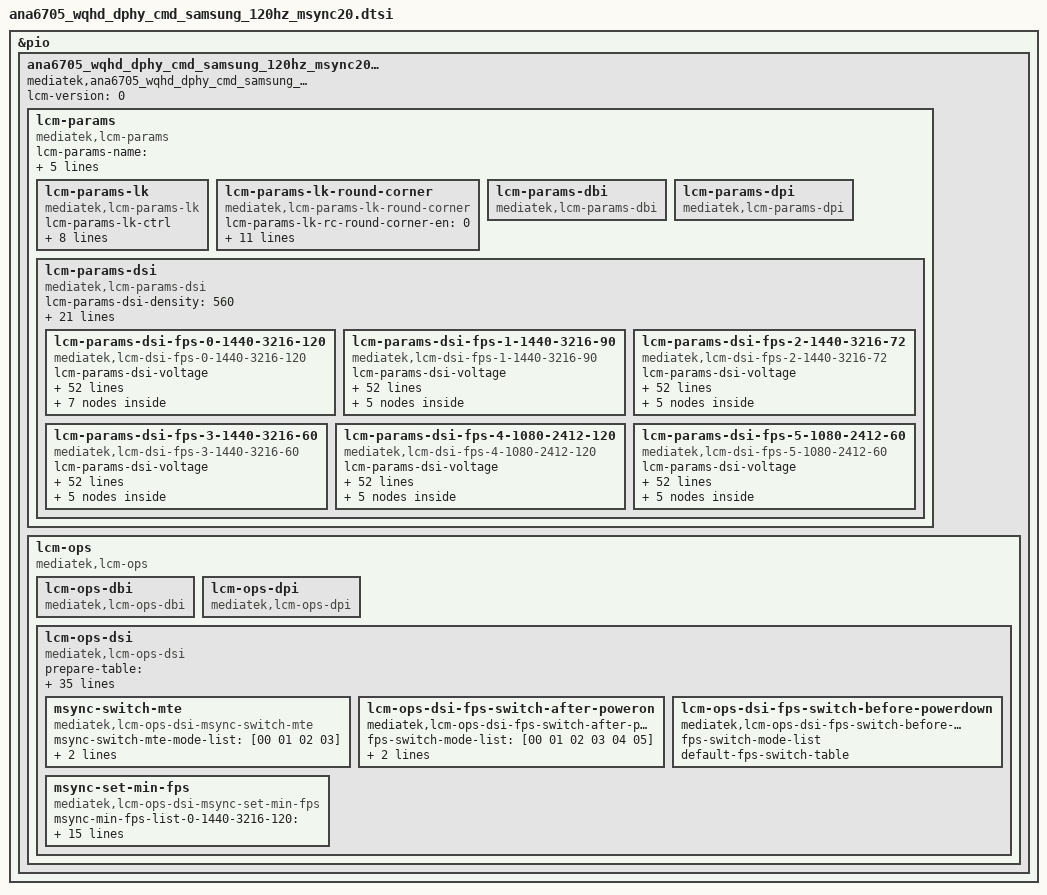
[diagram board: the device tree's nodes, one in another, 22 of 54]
// SPDX-License-Identifier: GPL-2.0-only OR BSD-2-Clause
/*
 * Device Tree defines for LCM settings
 * Copyright (c) 2021 MediaTek Inc.
 */

#include "mtk_lcm_settings.h"

&pio {
	ana6705_wqhd_dphy_cmd_samsung_120hz_msync20: ana6705-wqhd-dphy-cmd-samsung-120hz-msync20 {
		compatible = "mediatek,ana6705_wqhd_dphy_cmd_samsung_120hz_msync20";
		lcm-version = <0>;

		lcm-params{
			compatible = "mediatek,lcm-params";
			lcm-params-name = "ana6705-wqhd-dphy-cmd-samsung-120hz-msync20";
			lcm-params-types = <MTK_LCM_FUNC_DSI>;
			lcm-params-resolution = <1440 3216>;
			lcm-params-physical-width = <67>;
			lcm-params-physical-height = <149>;

			/* lk support */
			lcm-params-lk {
				compatible = "mediatek,lcm-params-lk";
				lcm-params-lk-ctrl;
				lcm-params-lk-lcm-if;
				lcm-params-lk-lcm-cmd-if;
				lcm-params-lk-io-select-mode;
				lcm-params-lk-lcm-x;
				lcm-params-lk-lcm-y;
				lcm-params-lk-virtual-resolution = <0 0>;
				lcm-params-lk-od-table-size;
				lcm-params-lk-od-table;
			};

			lcm-params-lk-round-corner {
				compatible = "mediatek,lcm-params-lk-round-corner";
				lcm-params-lk-rc-round-corner-en = <0>;
				lcm-params-lk-rc-is-notch;
				lcm-params-lk-rc-full-content = <0>;
				lcm-params-lk-rc-width;
				lcm-params-lk-rc-height;
				lcm-params-lk-rc-width-bot;
				lcm-params-lk-rc-height-bot;
				lcm-params-lk-rc-top-size;
				lcm-params-lk-rc-top-size-left;
				lcm-params-lk-rc-top-size-right;
				lcm-params-lk-rc-bottom-size;
				lcm-params-lk-rc-pattern-name;
			};

			lcm-params-dbi {
				compatible = "mediatek,lcm-params-dbi";
				/* future reserved for dbi interfaces */
			};

			lcm-params-dpi {
				compatible = "mediatek,lcm-params-dpi";
				/* future reserved for dpi interfaces */
			};

			lcm-params-dsi {
				compatible = "mediatek,lcm-params-dsi";
				lcm-params-dsi-density = <560>;
				lcm-params-dsi-lanes = <4>;
				lcm-params-dsi-format = <MTK_MIPI_DSI_FMT_RGB888>;
				lcm-params-dsi-phy-type = <MTK_LCM_MIPI_DPHY>;
				lcm-params-dsi-mode-flags = <MTK_MIPI_DSI_MODE_LPM>,
						<MTK_MIPI_DSI_MODE_EOT_PACKET>,
						<MTK_MIPI_DSI_CLOCK_NON_CONTINUOUS>;
				lcm-params-dsi-mode-flags-doze-on;
				lcm-params-dsi-mode-flags-doze-off;

				lcm-params-dsi-need-fake-resolution;
				lcm-params-dsi-fake-resolution;

				lcm-gpio-list = <&pio 42 0>, /* gpio list*/
					<&pio 28 0>,
					<&pio 29 0>;
				pinctrl-names = "gpio1", "gpio2", "gpio3";
				pinctrl-0;
				pinctrl-1;
				pinctrl-2;
				status = "okay";

				lcm-params-dsi-default-mode = <0>;
				lcm-params-dsi-mode-count = <6>;
				lcm-params-dsi-mode-list =
					<0 1440 3216 120>,
					<1 1440 3216 90>,
					<2 1440 3216 72>,
					<3 1440 3216 60>,
					<4 1080 2412 120>,
					<5 1080 2412 60>;

				lcm-params-dsi-fps-0-1440-3216-120 {
					compatible = "mediatek,lcm-dsi-fps-0-1440-3216-120";
					lcm-params-dsi-voltage;
					lcm-params-dsi-fake = <0>;

					/* drm-display-mode */
					lcm-params-dsi-vrefresh = <120>;
					lcm-params-dsi-vertical-sync-active = <8>;
					lcm-params-dsi-vertical-backporch = <8>;
					lcm-params-dsi-vertical-frontporch = <8>;
					lcm-params-dsi-vertical-active-line = <3216>;
					lcm-params-dsi-horizontal-sync-active = <10>;
					lcm-params-dsi-horizontal-backporch = <20>;
					lcm-params-dsi-horizontal-frontporch = <40>;
					lcm-params-dsi-horizontal-active-pixel = <1440>;
					lcm-params-dsi-pixel-clock = <584642>;
					lcm-params-dsi-hskew;
					lcm-params-dsi-vscan;

					/* mtk-panel-params */
					//lcm-params-dsi-lk-pll-clock = <718>;
					//lcm-params-dsi-lk-data-rate = <1436>;
					lcm-params-dsi-pll-clock = <834>;
					lcm-params-dsi-data-rate = <1668>;
					lcm-params-dsi-vfp-for-low-power;
					lcm-params-dsi-ssc-enable;
					lcm-params-dsi-ssc-range;
					lcm-params-dsi-lcm-color-mode;
					lcm-params-dsi-min-luminance;
					lcm-params-dsi-average-luminance;
					lcm-params-dsi-max-luminance;
					lcm-params-dsi-round-corner-en = <0>;
					lcm-params-dsi-corner-pattern-height;
					lcm-params-dsi-corner-pattern-height-bot;
					lcm-params-dsi-corner-pattern-tp-size;
					lcm-params-dsi-corner-pattern-tp-size-left;
					lcm-params-dsi-corner-pattern-tp-size-right;
					lcm-params-dsi-corner-pattern-name;
					lcm-params-dsi-physical-width-um;
					lcm-params-dsi-physical-height-um;
					lcm-params-dsi-output-mode =
						<MTK_LCM_PANEL_DSC_SINGLE_PORT>;
					lcm-params-dsi-lcm-cmd-if;
					lcm-params-dsi-hbm-en-time;
					lcm-params-dsi-hbm-dis-time;
					lcm-params-dsi-lcm-index;
					lcm-params-dsi-wait-sof-before-dec-vfp;
					lcm-params-dsi-doze-delay;
					lcm-params-dsi-lfr-enable;
					lcm-params-dsi-lfr-minimum-fps;
					lcm-params-dsi-msync2-enable = <1>;
					lcm-params-dsi-max-vfp-for-msync;

					/* lane swap */
					lcm-params-dsi-lane-swap-en;
					lcm-params-dsi-lane-swap0;
					lcm-params-dsi-lane-swap1;

					/* esd check table */
					lcm-params-dsi-cust-esd-check = <0>;
					lcm-params-dsi-esd-check-enable = <1>;
					lcm-params-dsi-lcm-esd-check-table0 = [0a 01 9c];
					lcm-params-dsi-lcm-esd-check-table1;
					lcm-params-dsi-lcm-esd-check-table2;

					/* fpga support */
					lcm-params-dsi-fpga-params-0-1440-3216-120 {
						compatible = "mediatek,lcm-dsi-fpga-params";

						lcm-params-dsi-lk-pll-div = <0 0>;
						lcm-params-dsi-lk-fbk-div = <1>;
					};

					/* lk support */
					lcm-params-dsi-lk-params-0-1440-3216-120 {
						compatible = "mediatek,lcm-dsi-lk-params";
						lcm-params-dsi-lk-mode = <MTK_LK_CMD_MODE>;
						lcm-params-dsi-lk-switch-mode;
						lcm-params-dsi-lk-switch-mode-enable = <0>;
						lcm-params-dsi-lk-dsi-wmem-conti;
						lcm-params-dsi-lk-dsi-rmem-conti;
						lcm-params-dsi-lk-vc-num;
						lcm-params-dsi-lk-data-format =
							<MTK_LCM_COLOR_ORDER_RGB>,
							<MTK_LCM_DSI_TRANS_SEQ_MSB_FIRST>,
							<MTK_LCM_DSI_PADDING_ON_LSB>,
							<MTK_LCM_DSI_FORMAT_RGB888>;
						lcm-params-dsi-lk-intermediat-buffer-num;
						lcm-params-dsi-lk-ps =
							<MTK_LCM_PACKED_PS_24BIT_RGB888>;
						lcm-params-dsi-lk-word-count;
						lcm-params-dsi-lk-packet-size = <256>;

						lcm-params-dsi-lk-horizontal-blanking-pixel;
						lcm-params-dsi-lk-bllp;
						lcm-params-dsi-lk-line-byte;
						lcm-params-dsi-lk-horizontal-sync-active-byte;
						lcm-params-dsi-lk-horizontal-backporch-byte;
						lcm-params-dsi-lk-horizontal-frontporch-byte;
						lcm-params-dsi-lk-rgb-byte;
						lcm-params-dsi-lk-horizontal-sync-active-word-count;
						lcm-params-dsi-lk-horizontal-backporch-word-count;
						lcm-params-dsi-lk-horizontal-frontporch-word-count;
						lcm-params-dsi-lk-pll-select;
						lcm-params-dsi-lk-pll-div;
						lcm-params-dsi-lk-fbk-div;
						lcm-params-dsi-lk-fbk-sel;
						lcm-params-dsi-lk-rg = <0 0 0>;
						lcm-params-dsi-lk-dsi-clock;
						lcm-params-dsi-lk-ssc-disable = <1>;
						lcm-params-dsi-lk-ssc-range;
						lcm-params-dsi-lk-compatibility-for-nvk;
						lcm-params-dsi-lk-cont-clock = <0>;
						lcm-params-dsi-lk-ufoe-enable;
						lcm-params-dsi-lk-ufoe-params = <0 0 0 0>;
						lcm-params-dsi-lk-edp-panel;
						lcm-params-dsi-lk-lcm-int-te-monitor;
						lcm-params-dsi-lk-lcm-int-te-period;
						lcm-params-dsi-lk-lcm-ext-te-monitor;
						lcm-params-dsi-lk-lcm-ext-te-period;
						lcm-params-dsi-lk-noncont-clock;
						lcm-params-dsi-lk-noncont-clock-period;
						lcm-params-dsi-lk-clk-lp-per-line-enable = <0>;
						lcm-params-dsi-lk-dual-dsi-type;
						lcm-params-dsi-lk-mixmode-enable;
						lcm-params-dsi-lk-mixmode-mipi-clock;
						lcm-params-dsi-lk-pwm-fps;
						lcm-params-dsi-lk-pll-clock-lp;
						lcm-params-dsi-lk-ulps-sw-enable;
						lcm-params-dsi-lk-null-packet-en;
						lcm-params-dsi-lk-vact-fps;
						lcm-params-dsi-lk-send-frame-enable;
						lcm-params-dsi-lk-lfr-enable;
						lcm-params-dsi-lk-lfr-mode;
						lcm-params-dsi-lk-lfr-type;
						lcm-params-dsi-lk-lfr-skip-num;
						lcm-params-dsi-lk-ext-te-edge;
						lcm-params-dsi-lk-eint-disable;
						lcm-params-dsi-lk-phy-sel = <0 0 0 0>;
					};

					lcm-params-dsi-dsc-params-0-1440-3216-120 {
						compatible =
							"mediatek,lcm-params-dsi-dsc-params";
						lcm-params-dsi-dsc-enable = <1>;
						lcm-params-dsi-dsc-enable-lk = <1>;
						lcm-params-dsi-dsc-ver = <17>;
						lcm-params-dsi-dsc-slice-mode = <1>;
						lcm-params-dsi-dsc-rgb-swap = <0>;
						lcm-params-dsi-dsc-cfg = <2088>;
						lcm-params-dsi-dsc-rct-on = <1>;
						lcm-params-dsi-dsc-bit-per-channel = <10>;
						lcm-params-dsi-dsc-line-buf-depth = <11>;
						lcm-params-dsi-dsc-bp-enable = <1>;
						lcm-params-dsi-dsc-bit-per-pixel = <128>;
						lcm-params-dsi-dsc-pic-height = <3216>;
						lcm-params-dsi-dsc-pic-width = <1440>;
						lcm-params-dsi-dsc-slice-height = <24>;
						lcm-params-dsi-dsc-slice-width = <720>;
						lcm-params-dsi-dsc-chunk-size = <720>;
						lcm-params-dsi-dsc-xmit-delay = <512>;
						lcm-params-dsi-dsc-dec-delay = <646>;
						lcm-params-dsi-dsc-scale-value = <32>;
						lcm-params-dsi-dsc-increment-interval = <643>;
						lcm-params-dsi-dsc-decrement-interval = <10>;
						lcm-params-dsi-dsc-line-bpg-offset = <13>;
						lcm-params-dsi-dsc-nfl-bpg-offset = <1158>;
						lcm-params-dsi-dsc-slice-bpg-offset = <814>;
						lcm-params-dsi-dsc-initial-offset = <6144>;
						lcm-params-dsi-dsc-final-offset = <4336>;
						lcm-params-dsi-dsc-flatness-minqp = <7>;
						lcm-params-dsi-dsc-flatness-maxqp = <16>;
						lcm-params-dsi-dsc-rc-model-size = <8192>;
						lcm-params-dsi-dsc-rc-edge-factor = <6>;
						lcm-params-dsi-dsc-rc-quant-incr-limit0 = <15>;
						lcm-params-dsi-dsc-rc-quant-incr-limit1 = <15>;
						lcm-params-dsi-dsc-rc-tgt-offset-hi = <3>;
						lcm-params-dsi-dsc-rc-tgt-offset-lo = <3>;
					};

					lcm-params-dsi-phy-timcon-params-0-1440-3216-120 {
						compatible =
							"mediatek,lcm-params-dsi-phy-timcon";
						lcm-params-dsi-phy-timcon-hs-trail;
						lcm-params-dsi-phy-timcon-hs-prpr;
						lcm-params-dsi-phy-timcon-hs-zero;
						lcm-params-dsi-phy-timcon-lpx;
						lcm-params-dsi-phy-timcon-ta-get;
						lcm-params-dsi-phy-timcon-ta-sure;
						lcm-params-dsi-phy-timcon-ta-go;
						lcm-params-dsi-phy-timcon-da-hs-exit;
						lcm-params-dsi-phy-timcon-clk-trail;
						lcm-params-dsi-phy-timcon-cont-det;
						lcm-params-dsi-phy-timcon-da-hs-sync;
						lcm-params-dsi-phy-timcon-clk-zero;
						lcm-params-dsi-phy-timcon-clk-prpr;
						lcm-params-dsi-phy-timcon-clk-exit;
						lcm-params-dsi-phy-timcon-clk-post;

						/* lk support */
						lcm-params-dsi-phy-timcon-lk-hs-trail;
						lcm-params-dsi-phy-timcon-lk-hs-zero;
						lcm-params-dsi-phy-timcon-lk-hs-prpr;
						lcm-params-dsi-phy-timcon-lk-lpx;
						lcm-params-dsi-phy-timcon-lk-ta-sack;
						lcm-params-dsi-phy-timcon-lk-ta-get;
						lcm-params-dsi-phy-timcon-lk-ta-sure;
						lcm-params-dsi-phy-timcon-lk-ta-go;
						lcm-params-dsi-phy-timcon-lk-clk-trail;
						lcm-params-dsi-phy-timcon-lk-clk-zero;
						lcm-params-dsi-phy-timcon-lk-lpx-wait;
						lcm-params-dsi-phy-timcon-lk-cont-det;
						lcm-params-dsi-phy-timcon-lk-clk-hs-prpr;
						lcm-params-dsi-phy-timcon-lk-clk-hs-post;
						lcm-params-dsi-phy-timcon-lk-da-hs-exit;
						lcm-params-dsi-phy-timcon-lk-clk-hs-exit;
					};

					lcm-params-dsi-dyn-params-0-1440-3216-120 {
						compatible =
							"mediatek,lcm-params-dsi-dyn";
						lcm-params-dsi-dyn-switch-en = <0>;
						lcm-params-dsi-dyn-pll-clk;
						lcm-params-dsi-dyn-data-rate;
						lcm-params-dsi-dyn-vsa;
						lcm-params-dsi-dyn-vbp;
						lcm-params-dsi-dyn-vfp;
						lcm-params-dsi-dyn-vfp-lp-dyn;
						lcm-params-dsi-dyn-vac;
						lcm-params-dsi-dyn-hsa;
						lcm-params-dsi-dyn-hbp;
						lcm-params-dsi-dyn-hfp;
						lcm-params-dsi-dyn-hac;
						lcm-params-dsi-dyn-max-vfp-for-msync-dyn;
					};

					lcm-params-dsi-dyn-fps-params-0-1440-3216-120 {
						compatible =
							"mediatek,lcm-params-dsi-dyn-fps";
						lcm-params-dsi-dyn-fps-switch-en = <0>;
						lcm-params-dsi-dyn-fps-vact-timing-fps;
						lcm-params-dsi-dyn-fps-data-rate;
						lcm-params-dsi-dyn-fps-dfps-cmd-table0;
						lcm-params-dsi-dyn-fps-dfps-cmd-table1;
						lcm-params-dsi-dyn-fps-dfps-cmd-table2;
						lcm-params-dsi-dyn-fps-dfps-cmd-table3;
						lcm-params-dsi-dyn-fps-dfps-cmd-table4;
						lcm-params-dsi-dyn-fps-dfps-cmd-table5;
						lcm-params-dsi-dyn-fps-dfps-cmd-table6;
						lcm-params-dsi-dyn-fps-dfps-cmd-table7;
						lcm-params-dsi-dyn-fps-dfps-cmd-table8;
						lcm-params-dsi-dyn-fps-dfps-cmd-table9;
						lcm-params-dsi-dyn-fps-dfps-cmd-table10;
						lcm-params-dsi-dyn-fps-dfps-cmd-table11;
						lcm-params-dsi-dyn-fps-dfps-cmd-table12;
						lcm-params-dsi-dyn-fps-dfps-cmd-table13;
						lcm-params-dsi-dyn-fps-dfps-cmd-table14;
						lcm-params-dsi-dyn-fps-dfps-cmd-table15;
						lcm-params-dsi-dyn-fps-dfps-cmd-table16;
						lcm-params-dsi-dyn-fps-dfps-cmd-table17;
						lcm-params-dsi-dyn-fps-dfps-cmd-table18;
						lcm-params-dsi-dyn-fps-dfps-cmd-table19;
					};

					lcm-params-dsi-msync-cmd-table-0-1440-3216-120 {
						compatible =
							"mediatek,lcm-params-dsi-msync-cmd-table";
						lcm-params-dsi-te-type = <MTK_LCM_MULTI_TE>;
						lcm-params-dsi-msync-max-fps = <120>;
						lcm-params-dsi-msync-min-fps = <20>;
						lcm-params-dsi-msync-level-num = <20>;
						lcm-params-dsi-delay-frame-num = <2>;
						lcm-params-dsi-mte-tb-count = <4>;
						lcm-params-dsi-mte-level-id =
							<0 1 2 3>;
						lcm-params-dsi-mte-level-fps =
							<60 72 90 120>;
						lcm-params-dsi-mte-max-fps =
							<60 72 90 120>;
						lcm-params-dsi-mte-min-fps =
							<40 45 51 60>;
					};
				};

				lcm-params-dsi-fps-1-1440-3216-90 {
					compatible = "mediatek,lcm-dsi-fps-1-1440-3216-90";
					lcm-params-dsi-voltage;
					lcm-params-dsi-fake = <0>;

					/* drm-display-mode */
					lcm-params-dsi-vrefresh = <90>;
					lcm-params-dsi-vertical-sync-active = <8>;
					lcm-params-dsi-vertical-backporch = <8>;
					lcm-params-dsi-vertical-frontporch = <8>;
					lcm-params-dsi-vertical-active-line = <3216>;
					lcm-params-dsi-horizontal-sync-active = <10>;
					lcm-params-dsi-horizontal-backporch = <20>;
					lcm-params-dsi-horizontal-frontporch = <40>;
					lcm-params-dsi-horizontal-active-pixel = <1440>;
					lcm-params-dsi-pixel-clock = <437870>;
					lcm-params-dsi-hskew;
					lcm-params-dsi-vscan;

					/* mtk-panel-params */
					lcm-params-dsi-pll-clock = <834>;
					lcm-params-dsi-data-rate = <1668>;
					lcm-params-dsi-vfp-for-low-power;
					lcm-params-dsi-ssc-enable;
					lcm-params-dsi-ssc-range;
					lcm-params-dsi-lcm-color-mode;
					lcm-params-dsi-min-luminance;
					lcm-params-dsi-average-luminance;
					lcm-params-dsi-max-luminance;
					lcm-params-dsi-round-corner-en = <0>;
					lcm-params-dsi-corner-pattern-height;
					lcm-params-dsi-corner-pattern-height-bot;
					lcm-params-dsi-corner-pattern-tp-size;
					lcm-params-dsi-corner-pattern-tp-size-left;
					lcm-params-dsi-corner-pattern-tp-size-right;
					lcm-params-dsi-corner-pattern-name;
					lcm-params-dsi-physical-width-um;
					lcm-params-dsi-physical-height-um;
					lcm-params-dsi-output-mode =
						<MTK_LCM_PANEL_DSC_SINGLE_PORT>;
					lcm-params-dsi-lcm-cmd-if;
					lcm-params-dsi-hbm-en-time;
					lcm-params-dsi-hbm-dis-time;
					lcm-params-dsi-lcm-index;
					lcm-params-dsi-wait-sof-before-dec-vfp;
					lcm-params-dsi-doze-delay;
					lcm-params-dsi-lfr-enable;
					lcm-params-dsi-lfr-minimum-fps;
					lcm-params-dsi-msync2-enable = <1>;
					lcm-params-dsi-max-vfp-for-msync;

					/* lane swap */
					lcm-params-dsi-lane-swap-en;
					lcm-params-dsi-lane-swap0;
					lcm-params-dsi-lane-swap1;

					/* esd check table */
					lcm-params-dsi-cust-esd-check = <0>;
					lcm-params-dsi-esd-check-enable = <1>;
					lcm-params-dsi-lcm-esd-check-table0 = [0a 01 9c];
					lcm-params-dsi-lcm-esd-check-table1;
					lcm-params-dsi-lcm-esd-check-table2;

					lcm-params-dsi-dsc-params-1-1440-3216-90 {
						compatible =
							"mediatek,lcm-params-dsi-dsc-params";
						lcm-params-dsi-dsc-enable = <1>;
						lcm-params-dsi-dsc-ver = <17>;
						lcm-params-dsi-dsc-slice-mode = <1>;
						lcm-params-dsi-dsc-rgb-swap = <0>;
						lcm-params-dsi-dsc-cfg = <2088>;
						lcm-params-dsi-dsc-rct-on = <1>;
						lcm-params-dsi-dsc-bit-per-channel = <10>;
						lcm-params-dsi-dsc-line-buf-depth = <11>;
						lcm-params-dsi-dsc-bp-enable = <1>;
						lcm-params-dsi-dsc-bit-per-pixel = <128>;
						lcm-params-dsi-dsc-pic-height = <3216>;
						lcm-params-dsi-dsc-pic-width = <1440>;
						lcm-params-dsi-dsc-slice-height = <24>;
						lcm-params-dsi-dsc-slice-width = <720>;
						lcm-params-dsi-dsc-chunk-size = <720>;
						lcm-params-dsi-dsc-xmit-delay = <512>;
						lcm-params-dsi-dsc-dec-delay = <646>;
						lcm-params-dsi-dsc-scale-value = <32>;
						lcm-params-dsi-dsc-increment-interval = <643>;
						lcm-params-dsi-dsc-decrement-interval = <10>;
						lcm-params-dsi-dsc-line-bpg-offset = <13>;
						lcm-params-dsi-dsc-nfl-bpg-offset = <1158>;
						lcm-params-dsi-dsc-slice-bpg-offset = <814>;
						lcm-params-dsi-dsc-initial-offset = <6144>;
						lcm-params-dsi-dsc-final-offset = <4336>;
						lcm-params-dsi-dsc-flatness-minqp = <7>;
						lcm-params-dsi-dsc-flatness-maxqp = <16>;
						lcm-params-dsi-dsc-rc-model-size = <8192>;
						lcm-params-dsi-dsc-rc-edge-factor = <6>;
						lcm-params-dsi-dsc-rc-quant-incr-limit0 = <15>;
						lcm-params-dsi-dsc-rc-quant-incr-limit1 = <15>;
						lcm-params-dsi-dsc-rc-tgt-offset-hi = <3>;
						lcm-params-dsi-dsc-rc-tgt-offset-lo = <3>;
					};

					lcm-params-dsi-phy-timcon-params-1-1440-3216-90 {
						compatible =
							"mediatek,lcm-params-dsi-phy-timcon";
						lcm-params-dsi-phy-timcon-hs-trail;
						lcm-params-dsi-phy-timcon-hs-prpr;
						lcm-params-dsi-phy-timcon-hs-zero;
						lcm-params-dsi-phy-timcon-lpx;
						lcm-params-dsi-phy-timcon-ta-get;
						lcm-params-dsi-phy-timcon-ta-sure;
						lcm-params-dsi-phy-timcon-ta-go;
						lcm-params-dsi-phy-timcon-da-hs-exit;
						lcm-params-dsi-phy-timcon-clk-trail;
						lcm-params-dsi-phy-timcon-cont-det;
						lcm-params-dsi-phy-timcon-da-hs-sync;
						lcm-params-dsi-phy-timcon-clk-zero;
						lcm-params-dsi-phy-timcon-clk-prpr;
						lcm-params-dsi-phy-timcon-clk-exit;
						lcm-params-dsi-phy-timcon-clk-post;
					};

					lcm-params-dsi-dyn-params-1-1440-3216-90 {
						compatible =
							"mediatek,lcm-params-dsi-dyn";
						lcm-params-dsi-dyn-switch-en = <0>;
						lcm-params-dsi-dyn-pll-clk;
						lcm-params-dsi-dyn-data-rate;
						lcm-params-dsi-dyn-vsa;
						lcm-params-dsi-dyn-vbp;
						lcm-params-dsi-dyn-vfp;
						lcm-params-dsi-dyn-vfp-lp-dyn;
						lcm-params-dsi-dyn-vac;
						lcm-params-dsi-dyn-hsa;
						lcm-params-dsi-dyn-hbp;
						lcm-params-dsi-dyn-hfp;
						lcm-params-dsi-dyn-hac;
						lcm-params-dsi-dyn-max-vfp-for-msync-dyn;
					};

					lcm-params-dsi-dyn-fps-params-1-1440-3216-90 {
						compatible =
							"mediatek,lcm-params-dsi-dyn-fps";
						lcm-params-dsi-dyn-fps-switch-en = <0>;
						lcm-params-dsi-dyn-fps-vact-timing-fps;
						lcm-params-dsi-dyn-fps-data-rate;
						lcm-params-dsi-dyn-fps-dfps-cmd-table0;
						lcm-params-dsi-dyn-fps-dfps-cmd-table1;
						lcm-params-dsi-dyn-fps-dfps-cmd-table2;
						lcm-params-dsi-dyn-fps-dfps-cmd-table3;
						lcm-params-dsi-dyn-fps-dfps-cmd-table4;
						lcm-params-dsi-dyn-fps-dfps-cmd-table5;
						lcm-params-dsi-dyn-fps-dfps-cmd-table6;
						lcm-params-dsi-dyn-fps-dfps-cmd-table7;
						lcm-params-dsi-dyn-fps-dfps-cmd-table8;
						lcm-params-dsi-dyn-fps-dfps-cmd-table9;
						lcm-params-dsi-dyn-fps-dfps-cmd-table10;
						lcm-params-dsi-dyn-fps-dfps-cmd-table11;
						lcm-params-dsi-dyn-fps-dfps-cmd-table12;
						lcm-params-dsi-dyn-fps-dfps-cmd-table13;
						lcm-params-dsi-dyn-fps-dfps-cmd-table14;
						lcm-params-dsi-dyn-fps-dfps-cmd-table15;
						lcm-params-dsi-dyn-fps-dfps-cmd-table16;
						lcm-params-dsi-dyn-fps-dfps-cmd-table17;
						lcm-params-dsi-dyn-fps-dfps-cmd-table18;
						lcm-params-dsi-dyn-fps-dfps-cmd-table19;
					};

					lcm-params-dsi-msync-cmd-table-1-1440-3216-90 {
						compatible =
							"mediatek,lcm-params-dsi-msync-cmd-table";
						lcm-params-dsi-te-type = <MTK_LCM_MULTI_TE>;
						lcm-params-dsi-msync-max-fps = <120>;
						lcm-params-dsi-msync-min-fps = <20>;
						lcm-params-dsi-msync-level-num = <20>;
						lcm-params-dsi-mte-tb-count = <4>;
						lcm-params-dsi-mte-level-id =
							<0 1 2 3>;
						lcm-params-dsi-mte-level-fps =
							<60 72 90 120>;
						lcm-params-dsi-mte-max-fps =
							<60 72 90 120>;
						lcm-params-dsi-mte-min-fps =
							<40 45 51 60>;
					};
				};

				lcm-params-dsi-fps-2-1440-3216-72 {
					compatible = "mediatek,lcm-dsi-fps-2-1440-3216-72";
					lcm-params-dsi-voltage;
					lcm-params-dsi-fake = <0>;

					/* drm-display-mode */
					lcm-params-dsi-vrefresh = <72>;
					lcm-params-dsi-vertical-sync-active = <8>;
					lcm-params-dsi-vertical-backporch = <8>;
					lcm-params-dsi-vertical-frontporch = <8>;
					lcm-params-dsi-vertical-active-line = <3216>;
					lcm-params-dsi-horizontal-sync-active = <10>;
					lcm-params-dsi-horizontal-backporch = <20>;
					lcm-params-dsi-horizontal-frontporch = <40>;
					lcm-params-dsi-horizontal-active-pixel = <1440>;
					lcm-params-dsi-pixel-clock = <349807>;
					lcm-params-dsi-hskew;
					lcm-params-dsi-vscan;

					/* mtk-panel-params */
					lcm-params-dsi-pll-clock = <834>;
					lcm-params-dsi-data-rate = <1668>;
					lcm-params-dsi-vfp-for-low-power;
					lcm-params-dsi-ssc-enable;
					lcm-params-dsi-ssc-range;
					lcm-params-dsi-lcm-color-mode;
					lcm-params-dsi-min-luminance;
					lcm-params-dsi-average-luminance;
					lcm-params-dsi-max-luminance;
					lcm-params-dsi-round-corner-en = <0>;
					lcm-params-dsi-corner-pattern-height;
					lcm-params-dsi-corner-pattern-height-bot;
					lcm-params-dsi-corner-pattern-tp-size;
					lcm-params-dsi-corner-pattern-tp-size-left;
					lcm-params-dsi-corner-pattern-tp-size-right;
					lcm-params-dsi-corner-pattern-name;
					lcm-params-dsi-physical-width-um;
					lcm-params-dsi-physical-height-um;
					lcm-params-dsi-output-mode =
						<MTK_LCM_PANEL_DSC_SINGLE_PORT>;
					lcm-params-dsi-lcm-cmd-if;
					lcm-params-dsi-hbm-en-time;
					lcm-params-dsi-hbm-dis-time;
					lcm-params-dsi-lcm-index;
					lcm-params-dsi-wait-sof-before-dec-vfp;
					lcm-params-dsi-doze-delay;
					lcm-params-dsi-lfr-enable;
					lcm-params-dsi-lfr-minimum-fps;
					lcm-params-dsi-msync2-enable = <1>;
					lcm-params-dsi-max-vfp-for-msync;

					/* lane swap */
					lcm-params-dsi-lane-swap-en;
					lcm-params-dsi-lane-swap0;
					lcm-params-dsi-lane-swap1;

					/* esd check table */
					lcm-params-dsi-cust-esd-check = <0>;
					lcm-params-dsi-esd-check-enable = <1>;
					lcm-params-dsi-lcm-esd-check-table0 = [0a 01 9c];
					lcm-params-dsi-lcm-esd-check-table1;
					lcm-params-dsi-lcm-esd-check-table2;

					lcm-params-dsi-dsc-params-2-1440-3216-72 {
						compatible =
							"mediatek,lcm-params-dsi-dsc-params";
						lcm-params-dsi-dsc-enable = <1>;
						lcm-params-dsi-dsc-ver = <17>;
						lcm-params-dsi-dsc-slice-mode = <1>;
						lcm-params-dsi-dsc-rgb-swap = <0>;
						lcm-params-dsi-dsc-cfg = <2088>;
						lcm-params-dsi-dsc-rct-on = <1>;
						lcm-params-dsi-dsc-bit-per-channel = <10>;
						lcm-params-dsi-dsc-line-buf-depth = <11>;
						lcm-params-dsi-dsc-bp-enable = <1>;
						lcm-params-dsi-dsc-bit-per-pixel = <128>;
						lcm-params-dsi-dsc-pic-height = <3216>;
						lcm-params-dsi-dsc-pic-width = <1440>;
						lcm-params-dsi-dsc-slice-height = <24>;
						lcm-params-dsi-dsc-slice-width = <720>;
						lcm-params-dsi-dsc-chunk-size = <720>;
						lcm-params-dsi-dsc-xmit-delay = <512>;
						lcm-params-dsi-dsc-dec-delay = <646>;
						lcm-params-dsi-dsc-scale-value = <32>;
						lcm-params-dsi-dsc-increment-interval = <643>;
						lcm-params-dsi-dsc-decrement-interval = <10>;
						lcm-params-dsi-dsc-line-bpg-offset = <13>;
						lcm-params-dsi-dsc-nfl-bpg-offset = <1158>;
						lcm-params-dsi-dsc-slice-bpg-offset = <814>;
						lcm-params-dsi-dsc-initial-offset = <6144>;
						lcm-params-dsi-dsc-final-offset = <4336>;
						lcm-params-dsi-dsc-flatness-minqp = <7>;
						lcm-params-dsi-dsc-flatness-maxqp = <16>;
						lcm-params-dsi-dsc-rc-model-size = <8192>;
						lcm-params-dsi-dsc-rc-edge-factor = <6>;
						lcm-params-dsi-dsc-rc-quant-incr-limit0 = <15>;
						lcm-params-dsi-dsc-rc-quant-incr-limit1 = <15>;
						lcm-params-dsi-dsc-rc-tgt-offset-hi = <3>;
						lcm-params-dsi-dsc-rc-tgt-offset-lo = <3>;
					};

					lcm-params-dsi-phy-timcon-params-2-1440-3216-72 {
						compatible =
							"mediatek,lcm-params-dsi-phy-timcon";
						lcm-params-dsi-phy-timcon-hs-trail;
						lcm-params-dsi-phy-timcon-hs-prpr;
						lcm-params-dsi-phy-timcon-hs-zero;
						lcm-params-dsi-phy-timcon-lpx;
						lcm-params-dsi-phy-timcon-ta-get;
						lcm-params-dsi-phy-timcon-ta-sure;
						lcm-params-dsi-phy-timcon-ta-go;
						lcm-params-dsi-phy-timcon-da-hs-exit;
						lcm-params-dsi-phy-timcon-clk-trail;
						lcm-params-dsi-phy-timcon-cont-det;
						lcm-params-dsi-phy-timcon-da-hs-sync;
						lcm-params-dsi-phy-timcon-clk-zero;
						lcm-params-dsi-phy-timcon-clk-prpr;
						lcm-params-dsi-phy-timcon-clk-exit;
						lcm-params-dsi-phy-timcon-clk-post;
					};

					lcm-params-dsi-dyn-params-2-1440-3216-72 {
						compatible =
							"mediatek,lcm-params-dsi-dyn";
						lcm-params-dsi-dyn-switch-en = <0>;
						lcm-params-dsi-dyn-pll-clk;
						lcm-params-dsi-dyn-data-rate;
						lcm-params-dsi-dyn-vsa;
						lcm-params-dsi-dyn-vbp;
						lcm-params-dsi-dyn-vfp;
						lcm-params-dsi-dyn-vfp-lp-dyn;
						lcm-params-dsi-dyn-vac;
						lcm-params-dsi-dyn-hsa;
						lcm-params-dsi-dyn-hbp;
						lcm-params-dsi-dyn-hfp;
						lcm-params-dsi-dyn-hac;
						lcm-params-dsi-dyn-max-vfp-for-msync-dyn;
					};

					lcm-params-dsi-dyn-fps-params-2-1440-3216-72 {
						compatible =
							"mediatek,lcm-params-dsi-dyn-fps";
						lcm-params-dsi-dyn-fps-switch-en = <0>;
						lcm-params-dsi-dyn-fps-vact-timing-fps;
						lcm-params-dsi-dyn-fps-data-rate;
						lcm-params-dsi-dyn-fps-dfps-cmd-table0;
						lcm-params-dsi-dyn-fps-dfps-cmd-table1;
						lcm-params-dsi-dyn-fps-dfps-cmd-table2;
						lcm-params-dsi-dyn-fps-dfps-cmd-table3;
						lcm-params-dsi-dyn-fps-dfps-cmd-table4;
						lcm-params-dsi-dyn-fps-dfps-cmd-table5;
						lcm-params-dsi-dyn-fps-dfps-cmd-table6;
						lcm-params-dsi-dyn-fps-dfps-cmd-table7;
						lcm-params-dsi-dyn-fps-dfps-cmd-table8;
						lcm-params-dsi-dyn-fps-dfps-cmd-table9;
						lcm-params-dsi-dyn-fps-dfps-cmd-table10;
						lcm-params-dsi-dyn-fps-dfps-cmd-table11;
						lcm-params-dsi-dyn-fps-dfps-cmd-table12;
						lcm-params-dsi-dyn-fps-dfps-cmd-table13;
						lcm-params-dsi-dyn-fps-dfps-cmd-table14;
						lcm-params-dsi-dyn-fps-dfps-cmd-table15;
						lcm-params-dsi-dyn-fps-dfps-cmd-table16;
						lcm-params-dsi-dyn-fps-dfps-cmd-table17;
						lcm-params-dsi-dyn-fps-dfps-cmd-table18;
						lcm-params-dsi-dyn-fps-dfps-cmd-table19;
					};

					lcm-params-dsi-msync-cmd-table-2-1440-3216-72 {
						compatible =
							"mediatek,lcm-params-dsi-msync-cmd-table";
						lcm-params-dsi-te-type = <MTK_LCM_MULTI_TE>;
						lcm-params-dsi-msync-max-fps = <120>;
						lcm-params-dsi-msync-min-fps = <20>;
						lcm-params-dsi-msync-level-num = <20>;
						lcm-params-dsi-mte-tb-count = <4>;
						lcm-params-dsi-mte-level-id =
							<0 1 2 3>;
						lcm-params-dsi-mte-level-fps =
							<60 72 90 120>;
						lcm-params-dsi-mte-max-fps =
							<60 72 90 120>;
						lcm-params-dsi-mte-min-fps =
							<40 45 51 60>;
					};
				};

				lcm-params-dsi-fps-3-1440-3216-60 {
					compatible = "mediatek,lcm-dsi-fps-3-1440-3216-60";
					lcm-params-dsi-voltage;
					lcm-params-dsi-fake = <0>;

					/* drm-display-mode */
					lcm-params-dsi-vrefresh = <60>;
					lcm-params-dsi-vertical-sync-active = <8>;
					lcm-params-dsi-vertical-backporch = <8>;
					lcm-params-dsi-vertical-frontporch = <8>;
					lcm-params-dsi-vertical-active-line = <3216>;
					lcm-params-dsi-horizontal-sync-active = <10>;
					lcm-params-dsi-horizontal-backporch = <20>;
					lcm-params-dsi-horizontal-frontporch = <40>;
					lcm-params-dsi-horizontal-active-pixel = <1440>;
					lcm-params-dsi-pixel-clock = <291098>;
					lcm-params-dsi-hskew;
					lcm-params-dsi-vscan;

					/* mtk-panel-params */
					lcm-params-dsi-pll-clock = <834>;
					lcm-params-dsi-data-rate = <1668>;
					lcm-params-dsi-vfp-for-low-power;
					lcm-params-dsi-ssc-enable;
					lcm-params-dsi-ssc-range;
					lcm-params-dsi-lcm-color-mode;
					lcm-params-dsi-min-luminance;
					lcm-params-dsi-average-luminance;
					lcm-params-dsi-max-luminance;
					lcm-params-dsi-round-corner-en = <0>;
					lcm-params-dsi-corner-pattern-height;
					lcm-params-dsi-corner-pattern-height-bot;
					lcm-params-dsi-corner-pattern-tp-size;
					lcm-params-dsi-corner-pattern-tp-size-left;
					lcm-params-dsi-corner-pattern-tp-size-right;
					lcm-params-dsi-corner-pattern-name;
					lcm-params-dsi-physical-width-um;
					lcm-params-dsi-physical-height-um;
					lcm-params-dsi-output-mode =
						<MTK_LCM_PANEL_DSC_SINGLE_PORT>;
					lcm-params-dsi-lcm-cmd-if;
					lcm-params-dsi-hbm-en-time;
					lcm-params-dsi-hbm-dis-time;
					lcm-params-dsi-lcm-index;
					lcm-params-dsi-wait-sof-before-dec-vfp;
					lcm-params-dsi-doze-delay;
					lcm-params-dsi-lfr-enable;
					lcm-params-dsi-lfr-minimum-fps;
					lcm-params-dsi-msync2-enable = <1>;
					lcm-params-dsi-max-vfp-for-msync;

					/* lane swap */
					lcm-params-dsi-lane-swap-en;
					lcm-params-dsi-lane-swap0;
					lcm-params-dsi-lane-swap1;

					/* esd check table */
					lcm-params-dsi-cust-esd-check = <0>;
					lcm-params-dsi-esd-check-enable = <1>;
					lcm-params-dsi-lcm-esd-check-table0 = [0a 01 9c];
					lcm-params-dsi-lcm-esd-check-table1;
					lcm-params-dsi-lcm-esd-check-table2;

					lcm-params-dsi-dsc-params-3-1440-3216-60 {
						compatible =
							"mediatek,lcm-params-dsi-dsc-params";
						lcm-params-dsi-dsc-enable = <1>;
						lcm-params-dsi-dsc-ver = <17>;
						lcm-params-dsi-dsc-slice-mode = <1>;
						lcm-params-dsi-dsc-rgb-swap = <0>;
						lcm-params-dsi-dsc-cfg = <2088>;
						lcm-params-dsi-dsc-rct-on = <1>;
						lcm-params-dsi-dsc-bit-per-channel = <10>;
						lcm-params-dsi-dsc-line-buf-depth = <11>;
						lcm-params-dsi-dsc-bp-enable = <1>;
						lcm-params-dsi-dsc-bit-per-pixel = <128>;
						lcm-params-dsi-dsc-pic-height = <3216>;
						lcm-params-dsi-dsc-pic-width = <1440>;
						lcm-params-dsi-dsc-slice-height = <24>;
						lcm-params-dsi-dsc-slice-width = <720>;
						lcm-params-dsi-dsc-chunk-size = <720>;
						lcm-params-dsi-dsc-xmit-delay = <512>;
						lcm-params-dsi-dsc-dec-delay = <646>;
						lcm-params-dsi-dsc-scale-value = <32>;
						lcm-params-dsi-dsc-increment-interval = <643>;
						lcm-params-dsi-dsc-decrement-interval = <10>;
						lcm-params-dsi-dsc-line-bpg-offset = <13>;
						lcm-params-dsi-dsc-nfl-bpg-offset = <1158>;
						lcm-params-dsi-dsc-slice-bpg-offset = <814>;
						lcm-params-dsi-dsc-initial-offset = <6144>;
						lcm-params-dsi-dsc-final-offset = <4336>;
						lcm-params-dsi-dsc-flatness-minqp = <7>;
						lcm-params-dsi-dsc-flatness-maxqp = <16>;
						lcm-params-dsi-dsc-rc-model-size = <8192>;
						lcm-params-dsi-dsc-rc-edge-factor = <6>;
						lcm-params-dsi-dsc-rc-quant-incr-limit0 = <15>;
						lcm-params-dsi-dsc-rc-quant-incr-limit1 = <15>;
						lcm-params-dsi-dsc-rc-tgt-offset-hi = <3>;
						lcm-params-dsi-dsc-rc-tgt-offset-lo = <3>;
					};

					lcm-params-dsi-phy-timcon-params-3-1440-3216-60 {
						compatible =
							"mediatek,lcm-params-dsi-phy-timcon";
						lcm-params-dsi-phy-timcon-hs-trail;
						lcm-params-dsi-phy-timcon-hs-prpr;
						lcm-params-dsi-phy-timcon-hs-zero;
						lcm-params-dsi-phy-timcon-lpx;
						lcm-params-dsi-phy-timcon-ta-get;
						lcm-params-dsi-phy-timcon-ta-sure;
						lcm-params-dsi-phy-timcon-ta-go;
						lcm-params-dsi-phy-timcon-da-hs-exit;
						lcm-params-dsi-phy-timcon-clk-trail;
						lcm-params-dsi-phy-timcon-cont-det;
						lcm-params-dsi-phy-timcon-da-hs-sync;
						lcm-params-dsi-phy-timcon-clk-zero;
						lcm-params-dsi-phy-timcon-clk-prpr;
						lcm-params-dsi-phy-timcon-clk-exit;
						lcm-params-dsi-phy-timcon-clk-post;
					};

					lcm-params-dsi-dyn-params-3-1440-3216-60 {
						compatible =
							"mediatek,lcm-params-dsi-dyn";
						lcm-params-dsi-dyn-switch-en = <0>;
						lcm-params-dsi-dyn-pll-clk;
						lcm-params-dsi-dyn-data-rate;
						lcm-params-dsi-dyn-vsa;
						lcm-params-dsi-dyn-vbp;
						lcm-params-dsi-dyn-vfp;
						lcm-params-dsi-dyn-vfp-lp-dyn;
						lcm-params-dsi-dyn-vac;
						lcm-params-dsi-dyn-hsa;
						lcm-params-dsi-dyn-hbp;
						lcm-params-dsi-dyn-hfp;
						lcm-params-dsi-dyn-hac;
						lcm-params-dsi-dyn-max-vfp-for-msync-dyn;
					};

					lcm-params-dsi-dyn-fps-params-3-1440-3216-60 {
						compatible =
							"mediatek,lcm-params-dsi-dyn-fps";
						lcm-params-dsi-dyn-fps-switch-en = <0>;
						lcm-params-dsi-dyn-fps-vact-timing-fps;
						lcm-params-dsi-dyn-fps-data-rate;
						lcm-params-dsi-dyn-fps-dfps-cmd-table0;
						lcm-params-dsi-dyn-fps-dfps-cmd-table1;
						lcm-params-dsi-dyn-fps-dfps-cmd-table2;
						lcm-params-dsi-dyn-fps-dfps-cmd-table3;
						lcm-params-dsi-dyn-fps-dfps-cmd-table4;
						lcm-params-dsi-dyn-fps-dfps-cmd-table5;
						lcm-params-dsi-dyn-fps-dfps-cmd-table6;
						lcm-params-dsi-dyn-fps-dfps-cmd-table7;
						lcm-params-dsi-dyn-fps-dfps-cmd-table8;
						lcm-params-dsi-dyn-fps-dfps-cmd-table9;
						lcm-params-dsi-dyn-fps-dfps-cmd-table10;
						lcm-params-dsi-dyn-fps-dfps-cmd-table11;
						lcm-params-dsi-dyn-fps-dfps-cmd-table12;
						lcm-params-dsi-dyn-fps-dfps-cmd-table13;
						lcm-params-dsi-dyn-fps-dfps-cmd-table14;
						lcm-params-dsi-dyn-fps-dfps-cmd-table15;
						lcm-params-dsi-dyn-fps-dfps-cmd-table16;
						lcm-params-dsi-dyn-fps-dfps-cmd-table17;
						lcm-params-dsi-dyn-fps-dfps-cmd-table18;
						lcm-params-dsi-dyn-fps-dfps-cmd-table19;
					};

					lcm-params-dsi-msync-cmd-table-3-1440-3216-60 {
						compatible =
							"mediatek,lcm-params-dsi-msync-cmd-table";
						lcm-params-dsi-te-type = <MTK_LCM_MULTI_TE>;
						lcm-params-dsi-msync-max-fps = <120>;
						lcm-params-dsi-msync-min-fps = <20>;
						lcm-params-dsi-msync-level-num = <20>;
						lcm-params-dsi-mte-tb-count = <4>;
						lcm-params-dsi-mte-level-id =
							<0 1 2 3>;
						lcm-params-dsi-mte-level-fps =
							<60 72 90 120>;
						lcm-params-dsi-mte-max-fps =
							<60 72 90 120>;
						lcm-params-dsi-mte-min-fps =
							<40 45 51 60>;
					};
				};

				lcm-params-dsi-fps-4-1080-2412-120 {
					compatible = "mediatek,lcm-dsi-fps-4-1080-2412-120";
					lcm-params-dsi-voltage;
					lcm-params-dsi-fake = <0>;

					/* drm-display-mode */
					lcm-params-dsi-vrefresh = <120>;
					lcm-params-dsi-vertical-sync-active = <8>;
					lcm-params-dsi-vertical-backporch = <8>;
					lcm-params-dsi-vertical-frontporch = <8>;
					lcm-params-dsi-vertical-active-line = <2412>;
					lcm-params-dsi-horizontal-sync-active = <10>;
					lcm-params-dsi-horizontal-backporch = <20>;
					lcm-params-dsi-horizontal-frontporch = <40>;
					lcm-params-dsi-horizontal-active-pixel = <1080>;
					lcm-params-dsi-pixel-clock = <336168>;
					lcm-params-dsi-hskew;
					lcm-params-dsi-vscan;

					/* mtk-panel-params */
					lcm-params-dsi-pll-clock = <488>;
					lcm-params-dsi-data-rate = <976>;
					lcm-params-dsi-vfp-for-low-power;
					lcm-params-dsi-ssc-enable;
					lcm-params-dsi-ssc-range;
					lcm-params-dsi-lcm-color-mode;
					lcm-params-dsi-min-luminance;
					lcm-params-dsi-average-luminance;
					lcm-params-dsi-max-luminance;
					lcm-params-dsi-round-corner-en = <0>;
					lcm-params-dsi-corner-pattern-height;
					lcm-params-dsi-corner-pattern-height-bot;
					lcm-params-dsi-corner-pattern-tp-size;
					lcm-params-dsi-corner-pattern-tp-size-left;
					lcm-params-dsi-corner-pattern-tp-size-right;
					lcm-params-dsi-corner-pattern-name;
					lcm-params-dsi-physical-width-um;
					lcm-params-dsi-physical-height-um;
					lcm-params-dsi-output-mode =
						<MTK_LCM_PANEL_DSC_SINGLE_PORT>;
					lcm-params-dsi-lcm-cmd-if;
					lcm-params-dsi-hbm-en-time;
					lcm-params-dsi-hbm-dis-time;
					lcm-params-dsi-lcm-index;
					lcm-params-dsi-wait-sof-before-dec-vfp;
					lcm-params-dsi-doze-delay;
					lcm-params-dsi-lfr-enable;
					lcm-params-dsi-lfr-minimum-fps;
					lcm-params-dsi-msync2-enable;
					lcm-params-dsi-max-vfp-for-msync;

					/* lane swap */
					lcm-params-dsi-lane-swap-en;
					lcm-params-dsi-lane-swap0;
					lcm-params-dsi-lane-swap1;

					/* esd check table */
					lcm-params-dsi-cust-esd-check = <0>;
					lcm-params-dsi-esd-check-enable = <1>;
					lcm-params-dsi-lcm-esd-check-table0 = [0a 01 9c];
					lcm-params-dsi-lcm-esd-check-table1;
					lcm-params-dsi-lcm-esd-check-table2;

					lcm-params-dsi-dsc-params-4-1080-2412-120 {
						compatible =
							"mediatek,lcm-params-dsi-dsc-params";
						lcm-params-dsi-dsc-enable = <1>;
						lcm-params-dsi-dsc-ver = <17>;
						lcm-params-dsi-dsc-slice-mode = <1>;
						lcm-params-dsi-dsc-rgb-swap = <0>;
						lcm-params-dsi-dsc-cfg = <2088>;
						lcm-params-dsi-dsc-rct-on = <1>;
						lcm-params-dsi-dsc-bit-per-channel = <10>;
						lcm-params-dsi-dsc-line-buf-depth = <11>;
						lcm-params-dsi-dsc-bp-enable = <1>;
						lcm-params-dsi-dsc-bit-per-pixel = <128>;
						lcm-params-dsi-dsc-pic-height = <2412>;
						lcm-params-dsi-dsc-pic-width = <1080>;
						lcm-params-dsi-dsc-slice-height = <36>;
						lcm-params-dsi-dsc-slice-width = <540>;
						lcm-params-dsi-dsc-chunk-size = <540>;
						lcm-params-dsi-dsc-xmit-delay = <512>;
						lcm-params-dsi-dsc-dec-delay = <571>;
						lcm-params-dsi-dsc-scale-value = <32>;
						lcm-params-dsi-dsc-increment-interval = <821>;
						lcm-params-dsi-dsc-decrement-interval = <7>;
						lcm-params-dsi-dsc-line-bpg-offset = <14>;
						lcm-params-dsi-dsc-nfl-bpg-offset = <820>;
						lcm-params-dsi-dsc-slice-bpg-offset = <724>;
						lcm-params-dsi-dsc-initial-offset = <6144>;
						lcm-params-dsi-dsc-final-offset = <4336>;
						lcm-params-dsi-dsc-flatness-minqp = <7>;
						lcm-params-dsi-dsc-flatness-maxqp = <16>;
						lcm-params-dsi-dsc-rc-model-size = <8192>;
						lcm-params-dsi-dsc-rc-edge-factor = <6>;
						lcm-params-dsi-dsc-rc-quant-incr-limit0 = <15>;
						lcm-params-dsi-dsc-rc-quant-incr-limit1 = <15>;
						lcm-params-dsi-dsc-rc-tgt-offset-hi = <3>;
						lcm-params-dsi-dsc-rc-tgt-offset-lo = <3>;
					};

					lcm-params-dsi-phy-timcon-params-4-1080-2412-120 {
						compatible =
							"mediatek,lcm-params-dsi-phy-timcon";
						lcm-params-dsi-phy-timcon-hs-trail;
						lcm-params-dsi-phy-timcon-hs-prpr;
						lcm-params-dsi-phy-timcon-hs-zero;
						lcm-params-dsi-phy-timcon-lpx;
						lcm-params-dsi-phy-timcon-ta-get;
						lcm-params-dsi-phy-timcon-ta-sure;
						lcm-params-dsi-phy-timcon-ta-go;
						lcm-params-dsi-phy-timcon-da-hs-exit;
						lcm-params-dsi-phy-timcon-clk-trail;
						lcm-params-dsi-phy-timcon-cont-det;
						lcm-params-dsi-phy-timcon-da-hs-sync;
						lcm-params-dsi-phy-timcon-clk-zero;
						lcm-params-dsi-phy-timcon-clk-prpr;
						lcm-params-dsi-phy-timcon-clk-exit;
						lcm-params-dsi-phy-timcon-clk-post;
					};

					lcm-params-dsi-dyn-params-4-1080-2412-120 {
						compatible =
							"mediatek,lcm-params-dsi-dyn";
						lcm-params-dsi-dyn-switch-en = <0>;
						lcm-params-dsi-dyn-pll-clk;
						lcm-params-dsi-dyn-data-rate;
						lcm-params-dsi-dyn-vsa;
						lcm-params-dsi-dyn-vbp;
						lcm-params-dsi-dyn-vfp;
						lcm-params-dsi-dyn-vfp-lp-dyn;
						lcm-params-dsi-dyn-vac;
						lcm-params-dsi-dyn-hsa;
						lcm-params-dsi-dyn-hbp;
						lcm-params-dsi-dyn-hfp;
						lcm-params-dsi-dyn-hac;
						lcm-params-dsi-dyn-max-vfp-for-msync-dyn;
					};

					lcm-params-dsi-dyn-fps-params-4-1080-2412-120 {
						compatible =
							"mediatek,lcm-params-dsi-dyn-fps";
						lcm-params-dsi-dyn-fps-switch-en = <1>;
						lcm-params-dsi-dyn-fps-vact-timing-fps = <120>;
						lcm-params-dsi-dyn-fps-data-rate;
						lcm-params-dsi-dyn-fps-dfps-cmd-table0;
						lcm-params-dsi-dyn-fps-dfps-cmd-table1;
						lcm-params-dsi-dyn-fps-dfps-cmd-table2;
						lcm-params-dsi-dyn-fps-dfps-cmd-table3;
						lcm-params-dsi-dyn-fps-dfps-cmd-table4;
						lcm-params-dsi-dyn-fps-dfps-cmd-table5;
						lcm-params-dsi-dyn-fps-dfps-cmd-table6;
						lcm-params-dsi-dyn-fps-dfps-cmd-table7;
						lcm-params-dsi-dyn-fps-dfps-cmd-table8;
						lcm-params-dsi-dyn-fps-dfps-cmd-table9;
						lcm-params-dsi-dyn-fps-dfps-cmd-table10;
						lcm-params-dsi-dyn-fps-dfps-cmd-table11;
						lcm-params-dsi-dyn-fps-dfps-cmd-table12;
						lcm-params-dsi-dyn-fps-dfps-cmd-table13;
						lcm-params-dsi-dyn-fps-dfps-cmd-table14;
						lcm-params-dsi-dyn-fps-dfps-cmd-table15;
						lcm-params-dsi-dyn-fps-dfps-cmd-table16;
						lcm-params-dsi-dyn-fps-dfps-cmd-table17;
						lcm-params-dsi-dyn-fps-dfps-cmd-table18;
						lcm-params-dsi-dyn-fps-dfps-cmd-table19;
					};

					lcm-params-dsi-msync-cmd-table-4-1080-2412-120 {
						compatible =
							"mediatek,lcm-params-dsi-msync-cmd-table";
						lcm-params-dsi-te-type;
						lcm-params-dsi-msync-max-fps;
						lcm-params-dsi-msync-min-fps;
						lcm-params-dsi-msync-level-num;
						lcm-params-dsi-delay-frame-num;
						lcm-params-dsi-mte-tb-count = <0>;
						lcm-params-dsi-mte-level-id;
						lcm-params-dsi-mte-level-fps;
						lcm-params-dsi-mte-max-fps;
						lcm-params-dsi-mte-min-fps;
					};
				};

				lcm-params-dsi-fps-5-1080-2412-60 {
					compatible = "mediatek,lcm-dsi-fps-5-1080-2412-60";
					lcm-params-dsi-voltage;
					lcm-params-dsi-fake = <0>;

					/* drm-display-mode */
					lcm-params-dsi-vrefresh = <60>;
					lcm-params-dsi-vertical-sync-active = <8>;
					lcm-params-dsi-vertical-backporch = <8>;
					lcm-params-dsi-vertical-frontporch = <8>;
					lcm-params-dsi-vertical-active-line = <2412>;
					lcm-params-dsi-horizontal-sync-active = <10>;
					lcm-params-dsi-horizontal-backporch = <20>;
					lcm-params-dsi-horizontal-frontporch = <40>;
					lcm-params-dsi-horizontal-active-pixel = <1080>;
					lcm-params-dsi-pixel-clock = <168084>;
					lcm-params-dsi-hskew;
					lcm-params-dsi-vscan;

					/* mtk-panel-params */
					lcm-params-dsi-pll-clock = <488>;
					lcm-params-dsi-data-rate = <976>;
					lcm-params-dsi-vfp-for-low-power;
					lcm-params-dsi-ssc-enable;
					lcm-params-dsi-ssc-range;
					lcm-params-dsi-lcm-color-mode;
					lcm-params-dsi-min-luminance;
					lcm-params-dsi-average-luminance;
					lcm-params-dsi-max-luminance;
					lcm-params-dsi-round-corner-en = <0>;
					lcm-params-dsi-corner-pattern-height;
					lcm-params-dsi-corner-pattern-height-bot;
					lcm-params-dsi-corner-pattern-tp-size;
					lcm-params-dsi-corner-pattern-tp-size-left;
					lcm-params-dsi-corner-pattern-tp-size-right;
					lcm-params-dsi-corner-pattern-name;
					lcm-params-dsi-physical-width-um;
					lcm-params-dsi-physical-height-um;
					lcm-params-dsi-output-mode =
						<MTK_LCM_PANEL_DSC_SINGLE_PORT>;
					lcm-params-dsi-lcm-cmd-if;
					lcm-params-dsi-hbm-en-time;
					lcm-params-dsi-hbm-dis-time;
					lcm-params-dsi-lcm-index;
					lcm-params-dsi-wait-sof-before-dec-vfp;
					lcm-params-dsi-doze-delay;
					lcm-params-dsi-lfr-enable;
					lcm-params-dsi-lfr-minimum-fps;
					lcm-params-dsi-msync2-enable;
					lcm-params-dsi-max-vfp-for-msync;

					/* lane swap */
					lcm-params-dsi-lane-swap-en;
					lcm-params-dsi-lane-swap0;
					lcm-params-dsi-lane-swap1;

					/* esd check table */
					lcm-params-dsi-cust-esd-check = <0>;
					lcm-params-dsi-esd-check-enable = <1>;
					lcm-params-dsi-lcm-esd-check-table0 = [0a 01 9c];
					lcm-params-dsi-lcm-esd-check-table1;
					lcm-params-dsi-lcm-esd-check-table2;

					lcm-params-dsi-dsc-params-5-1080-2412-60 {
						compatible =
							"mediatek,lcm-params-dsi-dsc-params";
						lcm-params-dsi-dsc-enable = <1>;
						lcm-params-dsi-dsc-ver = <17>;
						lcm-params-dsi-dsc-slice-mode = <1>;
						lcm-params-dsi-dsc-rgb-swap = <0>;
						lcm-params-dsi-dsc-cfg = <2088>;
						lcm-params-dsi-dsc-rct-on = <1>;
						lcm-params-dsi-dsc-bit-per-channel = <10>;
						lcm-params-dsi-dsc-line-buf-depth = <11>;
						lcm-params-dsi-dsc-bp-enable = <1>;
						lcm-params-dsi-dsc-bit-per-pixel = <128>;
						lcm-params-dsi-dsc-pic-height = <2412>;
						lcm-params-dsi-dsc-pic-width = <1080>;
						lcm-params-dsi-dsc-slice-height = <36>;
						lcm-params-dsi-dsc-slice-width = <540>;
						lcm-params-dsi-dsc-chunk-size = <540>;
						lcm-params-dsi-dsc-xmit-delay = <512>;
						lcm-params-dsi-dsc-dec-delay = <571>;
						lcm-params-dsi-dsc-scale-value = <32>;
						lcm-params-dsi-dsc-increment-interval = <821>;
						lcm-params-dsi-dsc-decrement-interval = <7>;
						lcm-params-dsi-dsc-line-bpg-offset = <14>;
						lcm-params-dsi-dsc-nfl-bpg-offset = <820>;
						lcm-params-dsi-dsc-slice-bpg-offset = <724>;
						lcm-params-dsi-dsc-initial-offset = <6144>;
						lcm-params-dsi-dsc-final-offset = <4336>;
						lcm-params-dsi-dsc-flatness-minqp = <7>;
						lcm-params-dsi-dsc-flatness-maxqp = <16>;
						lcm-params-dsi-dsc-rc-model-size = <8192>;
						lcm-params-dsi-dsc-rc-edge-factor = <6>;
						lcm-params-dsi-dsc-rc-quant-incr-limit0 = <15>;
						lcm-params-dsi-dsc-rc-quant-incr-limit1 = <15>;
						lcm-params-dsi-dsc-rc-tgt-offset-hi = <3>;
						lcm-params-dsi-dsc-rc-tgt-offset-lo = <3>;
					};

					lcm-params-dsi-phy-timcon-params-5-1080-2412-60 {
						compatible =
							"mediatek,lcm-params-dsi-phy-timcon";
						lcm-params-dsi-phy-timcon-hs-trail;
						lcm-params-dsi-phy-timcon-hs-prpr;
						lcm-params-dsi-phy-timcon-hs-zero;
						lcm-params-dsi-phy-timcon-lpx;
						lcm-params-dsi-phy-timcon-ta-get;
						lcm-params-dsi-phy-timcon-ta-sure;
						lcm-params-dsi-phy-timcon-ta-go;
						lcm-params-dsi-phy-timcon-da-hs-exit;
						lcm-params-dsi-phy-timcon-clk-trail;
						lcm-params-dsi-phy-timcon-cont-det;
						lcm-params-dsi-phy-timcon-da-hs-sync;
						lcm-params-dsi-phy-timcon-clk-zero;
						lcm-params-dsi-phy-timcon-clk-prpr;
						lcm-params-dsi-phy-timcon-clk-exit;
						lcm-params-dsi-phy-timcon-clk-post;
					};

					lcm-params-dsi-dyn-params-5-1080-2412-60 {
						compatible =
							"mediatek,lcm-params-dsi-dyn";
						lcm-params-dsi-dyn-switch-en = <0>;
						lcm-params-dsi-dyn-pll-clk;
						lcm-params-dsi-dyn-data-rate;
						lcm-params-dsi-dyn-vsa;
						lcm-params-dsi-dyn-vbp;
						lcm-params-dsi-dyn-vfp;
						lcm-params-dsi-dyn-vfp-lp-dyn;
						lcm-params-dsi-dyn-vac;
						lcm-params-dsi-dyn-hsa;
						lcm-params-dsi-dyn-hbp;
						lcm-params-dsi-dyn-hfp;
						lcm-params-dsi-dyn-hac;
						lcm-params-dsi-dyn-max-vfp-for-msync-dyn;
					};

					lcm-params-dsi-dyn-fps-params-5-1080-2412-60 {
						compatible =
							"mediatek,lcm-params-dsi-dyn-fps";
						lcm-params-dsi-dyn-fps-switch-en = <1>;
						lcm-params-dsi-dyn-fps-vact-timing-fps = <60>;
						lcm-params-dsi-dyn-fps-data-rate;
						lcm-params-dsi-dyn-fps-dfps-cmd-table0;
						lcm-params-dsi-dyn-fps-dfps-cmd-table1;
						lcm-params-dsi-dyn-fps-dfps-cmd-table2;
						lcm-params-dsi-dyn-fps-dfps-cmd-table3;
						lcm-params-dsi-dyn-fps-dfps-cmd-table4;
						lcm-params-dsi-dyn-fps-dfps-cmd-table5;
						lcm-params-dsi-dyn-fps-dfps-cmd-table6;
						lcm-params-dsi-dyn-fps-dfps-cmd-table7;
						lcm-params-dsi-dyn-fps-dfps-cmd-table8;
						lcm-params-dsi-dyn-fps-dfps-cmd-table9;
						lcm-params-dsi-dyn-fps-dfps-cmd-table10;
						lcm-params-dsi-dyn-fps-dfps-cmd-table11;
						lcm-params-dsi-dyn-fps-dfps-cmd-table12;
						lcm-params-dsi-dyn-fps-dfps-cmd-table13;
						lcm-params-dsi-dyn-fps-dfps-cmd-table14;
						lcm-params-dsi-dyn-fps-dfps-cmd-table15;
						lcm-params-dsi-dyn-fps-dfps-cmd-table16;
						lcm-params-dsi-dyn-fps-dfps-cmd-table17;
						lcm-params-dsi-dyn-fps-dfps-cmd-table18;
						lcm-params-dsi-dyn-fps-dfps-cmd-table19;
					};

					lcm-params-dsi-msync-cmd-table-5-1080-2412-60 {
						compatible =
							"mediatek,lcm-params-dsi-msync-cmd-table";
						lcm-params-dsi-te-type;
						lcm-params-dsi-msync-max-fps;
						lcm-params-dsi-msync-min-fps;
						lcm-params-dsi-msync-level-num;
						lcm-params-dsi-delay-frame-num;
						lcm-params-dsi-mte-tb-count = <0>;
						lcm-params-dsi-mte-level-id;
						lcm-params-dsi-mte-level-fps;
						lcm-params-dsi-mte-max-fps;
						lcm-params-dsi-mte-min-fps;
					};
				};
			};
		};

		lcm-ops {
			compatible = "mediatek,lcm-ops";
			lcm-ops-dbi {
				compatible = "mediatek,lcm-ops-dbi";
				/* future reserved for dbi interfaces*/
			};

			lcm-ops-dpi {
				compatible = "mediatek,lcm-ops-dpi";
				/* future reserved for dpi interfaces*/
			};

			lcm-ops-dsi {
				compatible = "mediatek,lcm-ops-dsi";
				prepare-table = [MTK_LCM_UTIL_TYPE_HEX_RESET 01 00],
					[MTK_LCM_UTIL_TYPE_HEX_MDELAY 01 0f],
					[MTK_LCM_UTIL_TYPE_HEX_RESET 01 01],
					[MTK_LCM_UTIL_TYPE_HEX_MDELAY 01 05],
					[MTK_LCM_UTIL_TYPE_HEX_RESET 01 00],
					[MTK_LCM_UTIL_TYPE_HEX_MDELAY 01 02],
					[MTK_LCM_UTIL_TYPE_HEX_RESET 01 01],
					[MTK_LCM_UTIL_TYPE_HEX_MDELAY 01 05],
	/* DSC Setting */
	/* Dsc 10bit input */

					[MTK_LCM_PHASE_TYPE_HEX_START 01 MTK_LCM_PHASE_HEX_KERNEL],
					/* wqhd 120 init*/
					[MTK_LCM_CMD_TYPE_HEX_WRITE_BUFFER_CONDITION 5c],
						[MTK_LCM_INPUT_TYPE_HEX_CURRENT_MODE 00 9E],
						[11 00 00 AB 30 80 0C 90 05],
						[A0 00 18 02 D0 02 D0 02 00],
						[02 86 00 20 02 83 00 0A 00],
						[0D 04 86 03 2E 18 00 10 F0],
						[07 10 20 00 06 0F 0F 33 0E],
						[1C 2A 38 46 54 62 69 70 77],
						[79 7B 7D 7E 02 02 22 00 2A],
						[40 2A BE 3A FC 3A FA 3A F8],
						[3B 38 3B 78 3B B6 4B B6 4B],
						[F4 4B F4 6C 34 84 74 00],
					/* wqhd 90 init*/
					[MTK_LCM_CMD_TYPE_HEX_WRITE_BUFFER_CONDITION 5c],
						[MTK_LCM_INPUT_TYPE_HEX_CURRENT_MODE 01 9E],
						[11 00 00 AB 30 80 0C 90 05],
						[A0 00 18 02 D0 02 D0 02 00],
						[02 86 00 20 02 83 00 0A 00],
						[0D 04 86 03 2E 18 00 10 F0],
						[07 10 20 00 06 0F 0F 33 0E],
						[1C 2A 38 46 54 62 69 70 77],
						[79 7B 7D 7E 02 02 22 00 2A],
						[40 2A BE 3A FC 3A FA 3A F8],
						[3B 38 3B 78 3B B6 4B B6 4B],
						[F4 4B F4 6C 34 84 74 00],
					/* wqhd 72 init*/
					[MTK_LCM_CMD_TYPE_HEX_WRITE_BUFFER_CONDITION 5c],
						[MTK_LCM_INPUT_TYPE_HEX_CURRENT_MODE 02 9E],
						[11 00 00 AB 30 80 0C 90 05],
						[A0 00 18 02 D0 02 D0 02 00],
						[02 86 00 20 02 83 00 0A 00],
						[0D 04 86 03 2E 18 00 10 F0],
						[07 10 20 00 06 0F 0F 33 0E],
						[1C 2A 38 46 54 62 69 70 77],
						[79 7B 7D 7E 02 02 22 00 2A],
						[40 2A BE 3A FC 3A FA 3A F8],
						[3B 38 3B 78 3B B6 4B B6 4B],
						[F4 4B F4 6C 34 84 74 00],
					/* wqhd 60 init*/
					[MTK_LCM_CMD_TYPE_HEX_WRITE_BUFFER_CONDITION 5c],
						[MTK_LCM_INPUT_TYPE_HEX_CURRENT_MODE 03 9E],
						[11 00 00 AB 30 80 0C 90 05],
						[A0 00 18 02 D0 02 D0 02 00],
						[02 86 00 20 02 83 00 0A 00],
						[0D 04 86 03 2E 18 00 10 F0],
						[07 10 20 00 06 0F 0F 33 0E],
						[1C 2A 38 46 54 62 69 70 77],
						[79 7B 7D 7E 02 02 22 00 2A],
						[40 2A BE 3A FC 3A FA 3A F8],
						[3B 38 3B 78 3B B6 4B B6 4B],
						[F4 4B F4 6C 34 84 74 00],
					/* fhd 120 init*/
					[MTK_LCM_CMD_TYPE_HEX_WRITE_BUFFER_CONDITION 5c],
						[MTK_LCM_INPUT_TYPE_HEX_CURRENT_MODE 04 9E 11],
						[00 00 AB 30 80 09 6C 04 38],
						[00 24 02 1C 02 1C 02 00 02],
						[3B 00 20 03 35 00 07 00 0E],
						[03 34 02 D4 18 00 10 F0 07],
						[10 20 00 06 0F 0F 33 0E 1C],
						[2A 38 46 54 62 69 70 77 79],
						[7B 7D 7E 02 02 22 00 2A 40],
						[2A BE 3A FC 3A FA 3A F8 3B],
						[38 3B 78 3B B6 4B B6 4B F4],
						[4B F4 6C 34 84 74 00],
					/* fhd 60 init*/
					[MTK_LCM_CMD_TYPE_HEX_WRITE_BUFFER_CONDITION 5c],
						[MTK_LCM_INPUT_TYPE_HEX_CURRENT_MODE 05 9E 11],
						[00 00 AB 30 80 09 6C 04 38],
						[00 24 02 1C 02 1C 02 00 02],
						[3B 00 20 03 35 00 07 00 0E],
						[03 34 02 D4 18 00 10 F0 07],
						[10 20 00 06 0F 0F 33 0E 1C],
						[2A 38 46 54 62 69 70 77 79],
						[7B 7D 7E 02 02 22 00 2A 40],
						[2A BE 3A FC 3A FA 3A F8 3B],
						[38 3B 78 3B B6 4B B6 4B F4],
						[4B F4 6C 34 84 74 00],
					[MTK_LCM_PHASE_TYPE_HEX_END 01 MTK_LCM_PHASE_HEX_KERNEL],

					[MTK_LCM_PHASE_TYPE_HEX_START 02 MTK_LCM_PHASE_HEX_LK],
						[MTK_LCM_PHASE_HEX_LK_DISPLAY_ON_DELAY],
					[MTK_LCM_CMD_TYPE_HEX_WRITE_BUFFER 81 9E],
						[11 00 00 AB 30 80 0C 90 05],
						[A0 00 18 02 D0 02 D0 02 00],
						[02 86 00 20 02 83 00 0A 00],
						[0D 04 86 03 2E 18 00 10 F0],
						[07 10 20 00 06 0F 0F 33 0E],
						[1C 2A 38 46 54 62 69 70 77],
						[79 7B 7D 7E 02 02 22 00 2A],
						[40 2A BE 3A FC 3A FA 3A F8],
						[3B 38 3B 78 3B B6 4B B6 4B],
						[F4 4B F4 6C 34 84 74 00 00],
						[00 00 00 00 00 00 00 00 00],
						[00 00 00 00 00 00 00 00 00],
						[00 00 00 00 00 00 00 00 00],
						[00 00 00 00 00 00 00 00 00],
						[00 00],
					[MTK_LCM_PHASE_TYPE_HEX_END 02 MTK_LCM_PHASE_HEX_LK],
						[MTK_LCM_PHASE_HEX_LK_DISPLAY_ON_DELAY],

	/* Sleep Out(11h) */
					[MTK_LCM_CMD_TYPE_HEX_WRITE_BUFFER 02],
							[9D 01],
					[MTK_LCM_CMD_TYPE_HEX_WRITE_BUFFER 01 11],

					[MTK_LCM_PHASE_TYPE_HEX_START 01 MTK_LCM_PHASE_HEX_KERNEL],
					[MTK_LCM_UTIL_TYPE_HEX_MDELAY 01 1e],
					[MTK_LCM_PHASE_TYPE_HEX_END 01 MTK_LCM_PHASE_HEX_KERNEL],

					[MTK_LCM_PHASE_TYPE_HEX_START 02 MTK_LCM_PHASE_HEX_LK],
						[MTK_LCM_PHASE_HEX_LK_DISPLAY_ON_DELAY],
					[MTK_LCM_UTIL_TYPE_HEX_MDELAY 01 78],
					[MTK_LCM_PHASE_TYPE_HEX_END 02 MTK_LCM_PHASE_HEX_LK],
						[MTK_LCM_PHASE_HEX_LK_DISPLAY_ON_DELAY],

	/* TSP_SYNC1 Fixed Setting */
					[MTK_LCM_CMD_TYPE_HEX_WRITE_BUFFER 03],
							[F0 5A 5A],
					[MTK_LCM_CMD_TYPE_HEX_WRITE_BUFFER 04],
							[B0 00 22 B9],
					[MTK_LCM_CMD_TYPE_HEX_WRITE_BUFFER 03],
							[B9 A1 B1],
					[MTK_LCM_CMD_TYPE_HEX_WRITE_BUFFER 04],
							[B0 00 3A B9],
	/* TSP_VSYNC Fixed TE 02:120 03:90 05:60 */
					[MTK_LCM_PHASE_TYPE_HEX_START 01 MTK_LCM_PHASE_HEX_KERNEL],
					/* wqhd 120 init*/
					[MTK_LCM_CMD_TYPE_HEX_WRITE_BUFFER_CONDITION 04],
						[MTK_LCM_INPUT_TYPE_HEX_CURRENT_MODE 00 B9 02],
					/* wqhd 90 init*/
					[MTK_LCM_CMD_TYPE_HEX_WRITE_BUFFER_CONDITION 04],
						[MTK_LCM_INPUT_TYPE_HEX_CURRENT_MODE 01 B9 03],
					/* wqhd 72 init*/
					[MTK_LCM_CMD_TYPE_HEX_WRITE_BUFFER_CONDITION 04],
						[MTK_LCM_INPUT_TYPE_HEX_CURRENT_MODE 02 B9 04],
					/* wqhd 60 init*/
					[MTK_LCM_CMD_TYPE_HEX_WRITE_BUFFER_CONDITION 04],
						[MTK_LCM_INPUT_TYPE_HEX_CURRENT_MODE 03 B9 05],
					/* fhd 120 init*/
					[MTK_LCM_CMD_TYPE_HEX_WRITE_BUFFER_CONDITION 04],
						[MTK_LCM_INPUT_TYPE_HEX_CURRENT_MODE 04 B9 02],
					/* fhd 60 init*/
					[MTK_LCM_CMD_TYPE_HEX_WRITE_BUFFER_CONDITION 04],
						[MTK_LCM_INPUT_TYPE_HEX_CURRENT_MODE 05 B9 05],
					[MTK_LCM_PHASE_TYPE_HEX_END 01 MTK_LCM_PHASE_HEX_KERNEL],

					[MTK_LCM_PHASE_TYPE_HEX_START 02 MTK_LCM_PHASE_HEX_LK],
						[MTK_LCM_PHASE_HEX_LK_DISPLAY_ON_DELAY],
					[MTK_LCM_CMD_TYPE_HEX_WRITE_BUFFER 02],
							[B9 02],
					[MTK_LCM_PHASE_TYPE_HEX_END 02 MTK_LCM_PHASE_HEX_LK],
						[MTK_LCM_PHASE_HEX_LK_DISPLAY_ON_DELAY],

					[MTK_LCM_CMD_TYPE_HEX_WRITE_BUFFER 04],
							[B0 00 26 B9],
					[MTK_LCM_CMD_TYPE_HEX_WRITE_BUFFER 03],
							[B9 00 00],
					[MTK_LCM_CMD_TYPE_HEX_WRITE_BUFFER 02],
							[F7 0F],
					[MTK_LCM_CMD_TYPE_HEX_WRITE_BUFFER 03],
							[F0 A5 A5],

	/* TSP_SYNC3 Fixed Setting */
					[MTK_LCM_CMD_TYPE_HEX_WRITE_BUFFER 03],
							[F0 5A 5A],
					[MTK_LCM_CMD_TYPE_HEX_WRITE_BUFFER 04],
							[B0 00 24 B9],
					[MTK_LCM_CMD_TYPE_HEX_WRITE_BUFFER 02],
							[B9 21],
					[MTK_LCM_CMD_TYPE_HEX_WRITE_BUFFER 04],
							[B0 00 38 B9],
	/* TSP_VSYNC Fixed TE 02:120 03:90 05:60 */
					[MTK_LCM_PHASE_TYPE_HEX_START 01 MTK_LCM_PHASE_HEX_KERNEL],
					/* wqhd 120 init*/
					[MTK_LCM_CMD_TYPE_HEX_WRITE_BUFFER_CONDITION 04],
						[MTK_LCM_INPUT_TYPE_HEX_CURRENT_MODE 00 B9 02],
					/* wqhd 90 init*/
					[MTK_LCM_CMD_TYPE_HEX_WRITE_BUFFER_CONDITION 04],
						[MTK_LCM_INPUT_TYPE_HEX_CURRENT_MODE 01 B9 03],
					/* wqhd 72 init*/
					[MTK_LCM_CMD_TYPE_HEX_WRITE_BUFFER_CONDITION 04],
						[MTK_LCM_INPUT_TYPE_HEX_CURRENT_MODE 02 B9 04],
					/* wqhd 60 init*/
					[MTK_LCM_CMD_TYPE_HEX_WRITE_BUFFER_CONDITION 04],
						[MTK_LCM_INPUT_TYPE_HEX_CURRENT_MODE 03 B9 05],
					/* fhd 120 init*/
					[MTK_LCM_CMD_TYPE_HEX_WRITE_BUFFER_CONDITION 04],
						[MTK_LCM_INPUT_TYPE_HEX_CURRENT_MODE 04 B9 02],
					/* fhd 60 init*/
					[MTK_LCM_CMD_TYPE_HEX_WRITE_BUFFER_CONDITION 04],
						[MTK_LCM_INPUT_TYPE_HEX_CURRENT_MODE 05 B9 05],
					[MTK_LCM_PHASE_TYPE_HEX_END 01 MTK_LCM_PHASE_HEX_KERNEL],

					[MTK_LCM_PHASE_TYPE_HEX_START 02 MTK_LCM_PHASE_HEX_LK],
						[MTK_LCM_PHASE_HEX_LK_DISPLAY_ON_DELAY],
					[MTK_LCM_CMD_TYPE_HEX_WRITE_BUFFER 02],
							[B9 02],
					[MTK_LCM_PHASE_TYPE_HEX_END 02 MTK_LCM_PHASE_HEX_LK],
						[MTK_LCM_PHASE_HEX_LK_DISPLAY_ON_DELAY],

					[MTK_LCM_CMD_TYPE_HEX_WRITE_BUFFER 04],
							[B0 00 2A B9],
					[MTK_LCM_CMD_TYPE_HEX_WRITE_BUFFER 03],
							[B9 00 00],
					[MTK_LCM_CMD_TYPE_HEX_WRITE_BUFFER 02],
							[F7 0F],
					[MTK_LCM_CMD_TYPE_HEX_WRITE_BUFFER 03],
							[F0 A5 A5],

    /* 120hz Transition */
					[MTK_LCM_PHASE_TYPE_HEX_START 02 MTK_LCM_PHASE_HEX_LK],
						[MTK_LCM_PHASE_HEX_LK_DISPLAY_ON_DELAY],
					[MTK_LCM_CMD_TYPE_HEX_WRITE_BUFFER 03],
						[F0 5A 5A],
					[MTK_LCM_CMD_TYPE_HEX_WRITE_BUFFER 04],
						[B0 00 16 F2],
					[MTK_LCM_CMD_TYPE_HEX_WRITE_BUFFER 03],
						[F2 1B 50],
					[MTK_LCM_CMD_TYPE_HEX_WRITE_BUFFER 03],
						[BD 21 02],
					[MTK_LCM_CMD_TYPE_HEX_WRITE_BUFFER 02 60 00],
					[MTK_LCM_CMD_TYPE_HEX_WRITE_BUFFER 04],
						[B0 00 10 BD],
					[MTK_LCM_CMD_TYPE_HEX_WRITE_BUFFER 02 BD 10],
					[MTK_LCM_CMD_TYPE_HEX_WRITE_BUFFER 02 F7 0F],
					[MTK_LCM_CMD_TYPE_HEX_WRITE_BUFFER 03],
						[F0 A5 A5],
					[MTK_LCM_PHASE_TYPE_HEX_END 02 MTK_LCM_PHASE_HEX_LK],
						[MTK_LCM_PHASE_HEX_LK_DISPLAY_ON_DELAY],

	/* Common Setting */
					[MTK_LCM_CMD_TYPE_HEX_WRITE_BUFFER 03],
							[F0 5A 5A],
					[MTK_LCM_CMD_TYPE_HEX_WRITE_BUFFER 03],
							[F2 00 01],
					[MTK_LCM_CMD_TYPE_HEX_WRITE_BUFFER 03],
							[F0 A5 A5],

	/* TE(Vsync) ON */
					[MTK_LCM_CMD_TYPE_HEX_WRITE_BUFFER 03],
							[F0 5A 5A],
					[MTK_LCM_CMD_TYPE_HEX_WRITE_BUFFER 02],
							[35 00],
					[MTK_LCM_PHASE_TYPE_HEX_START 01 MTK_LCM_PHASE_HEX_KERNEL],
					[MTK_LCM_CMD_TYPE_HEX_WRITE_BUFFER 02],
							[B9 02],
					[MTK_LCM_PHASE_TYPE_HEX_END 01 MTK_LCM_PHASE_HEX_KERNEL],
					[MTK_LCM_CMD_TYPE_HEX_WRITE_BUFFER 03],
							[F0 A5 A5],

	/* CASET/PASET Setting */
					[MTK_LCM_PHASE_TYPE_HEX_START 01 MTK_LCM_PHASE_HEX_KERNEL],
					/* wqhd 120 init*/
					[MTK_LCM_CMD_TYPE_HEX_WRITE_BUFFER_CONDITION 07],
						[MTK_LCM_INPUT_TYPE_HEX_CURRENT_MODE 00],
						[2A 00 00 05 9F],
					[MTK_LCM_CMD_TYPE_HEX_WRITE_BUFFER_CONDITION 07],
						[MTK_LCM_INPUT_TYPE_HEX_CURRENT_MODE 00],
						[2B 00 00 0C 8F],

					/* wqhd 90 init*/
					[MTK_LCM_CMD_TYPE_HEX_WRITE_BUFFER_CONDITION 07],
						[MTK_LCM_INPUT_TYPE_HEX_CURRENT_MODE 01],
						[2A 00 00 05 9F],
					[MTK_LCM_CMD_TYPE_HEX_WRITE_BUFFER_CONDITION 07],
						[MTK_LCM_INPUT_TYPE_HEX_CURRENT_MODE 01],
						[2B 00 00 0C 8F],

					/* wqhd 72 init*/
					[MTK_LCM_CMD_TYPE_HEX_WRITE_BUFFER_CONDITION 07],
						[MTK_LCM_INPUT_TYPE_HEX_CURRENT_MODE 02],
						[2A 00 00 05 9F],
					[MTK_LCM_CMD_TYPE_HEX_WRITE_BUFFER_CONDITION 07],
						[MTK_LCM_INPUT_TYPE_HEX_CURRENT_MODE 02],
						[2B 00 00 0C 8F],

					/* wqhd 60 init*/
					[MTK_LCM_CMD_TYPE_HEX_WRITE_BUFFER_CONDITION 07],
						[MTK_LCM_INPUT_TYPE_HEX_CURRENT_MODE 03],
						[2A 00 00 05 9F],
					[MTK_LCM_CMD_TYPE_HEX_WRITE_BUFFER_CONDITION 07],
						[MTK_LCM_INPUT_TYPE_HEX_CURRENT_MODE 03],
						[2B 00 00 0C 8F],

					/* fhd 120 init*/
					[MTK_LCM_CMD_TYPE_HEX_WRITE_BUFFER_CONDITION 07],
						[MTK_LCM_INPUT_TYPE_HEX_CURRENT_MODE 04],
						[2A 00 00 04 37],
					[MTK_LCM_CMD_TYPE_HEX_WRITE_BUFFER_CONDITION 07],
						[MTK_LCM_INPUT_TYPE_HEX_CURRENT_MODE 04],
						[2B 00 00 09 6b],

					/* fhd 60 init*/
					[MTK_LCM_CMD_TYPE_HEX_WRITE_BUFFER_CONDITION 07],
						[MTK_LCM_INPUT_TYPE_HEX_CURRENT_MODE 05],
						[2A 00 00 04 37],
					[MTK_LCM_CMD_TYPE_HEX_WRITE_BUFFER_CONDITION 07],
						[MTK_LCM_INPUT_TYPE_HEX_CURRENT_MODE 05],
						[2B 00 00 09 6b],
					[MTK_LCM_PHASE_TYPE_HEX_END 01 MTK_LCM_PHASE_HEX_KERNEL],

					[MTK_LCM_PHASE_TYPE_HEX_START 02 MTK_LCM_PHASE_HEX_LK],
						[MTK_LCM_PHASE_HEX_LK_DISPLAY_ON_DELAY],
					[MTK_LCM_CMD_TYPE_HEX_WRITE_BUFFER 05],
							[2A 00 00 05 9F],
					[MTK_LCM_CMD_TYPE_HEX_WRITE_BUFFER 05],
							[2B 00 00 0C 8F],
					[MTK_LCM_PHASE_TYPE_HEX_END 02 MTK_LCM_PHASE_HEX_LK],
						[MTK_LCM_PHASE_HEX_LK_DISPLAY_ON_DELAY],

	/* Scaler Setting */
					[MTK_LCM_CMD_TYPE_HEX_WRITE_BUFFER 03],
							[F0 5A 5A],

					[MTK_LCM_PHASE_TYPE_HEX_START 01 MTK_LCM_PHASE_HEX_KERNEL],
					/* wqhd 120 init*/
					[MTK_LCM_CMD_TYPE_HEX_WRITE_BUFFER_CONDITION 04],
						[MTK_LCM_INPUT_TYPE_HEX_CURRENT_MODE 00 C3 00],
					/* wqhd 90 init*/
					[MTK_LCM_CMD_TYPE_HEX_WRITE_BUFFER_CONDITION 04],
						[MTK_LCM_INPUT_TYPE_HEX_CURRENT_MODE 01 C3 00],
					/* wqhd 72 init*/
					[MTK_LCM_CMD_TYPE_HEX_WRITE_BUFFER_CONDITION 04],
						[MTK_LCM_INPUT_TYPE_HEX_CURRENT_MODE 02 C3 00],
					/* wqhd 60 init*/
					[MTK_LCM_CMD_TYPE_HEX_WRITE_BUFFER_CONDITION 04],
						[MTK_LCM_INPUT_TYPE_HEX_CURRENT_MODE 03 C3 00],

					/* fhd 120 init*/
					[MTK_LCM_CMD_TYPE_HEX_WRITE_BUFFER_CONDITION 04],
						[MTK_LCM_INPUT_TYPE_HEX_CURRENT_MODE 04 C3 89],
					[MTK_LCM_CMD_TYPE_HEX_WRITE_BUFFER_CONDITION 06],
						[MTK_LCM_INPUT_TYPE_HEX_CURRENT_MODE 04],
						[B0 00 24 C3],
					[MTK_LCM_CMD_TYPE_HEX_WRITE_BUFFER_CONDITION 14],
						[MTK_LCM_INPUT_TYPE_HEX_CURRENT_MODE 04],
						[C3 FD 00 FD 00 FD 00 FD 00 FD],
						[00 FD 00 FD 00 FD 00 FD],
					[MTK_LCM_CMD_TYPE_HEX_WRITE_BUFFER_CONDITION 06],
						[MTK_LCM_INPUT_TYPE_HEX_CURRENT_MODE 04],
						[B0 00 3A C3],
					[MTK_LCM_CMD_TYPE_HEX_WRITE_BUFFER_CONDITION 14],
						[MTK_LCM_INPUT_TYPE_HEX_CURRENT_MODE 04],
						[C3 B0 00 B0 00 B0 00 B0 00 B0],
						[00 B0 00 B0 00 B0 00 B0],
					[MTK_LCM_CMD_TYPE_HEX_WRITE_BUFFER_CONDITION 06],
						[MTK_LCM_INPUT_TYPE_HEX_CURRENT_MODE 04],
						[B0 00 50 C3],
					[MTK_LCM_CMD_TYPE_HEX_WRITE_BUFFER_CONDITION 14],
						[MTK_LCM_INPUT_TYPE_HEX_CURRENT_MODE 04],
						[C3 43 00 43 00 43 00 43 00 43],
						[00 43 00 43 00 43 00 43],
					[MTK_LCM_CMD_TYPE_HEX_WRITE_BUFFER_CONDITION 06],
						[MTK_LCM_INPUT_TYPE_HEX_CURRENT_MODE 04],
						[B0 00 61 C3],
					[MTK_LCM_CMD_TYPE_HEX_WRITE_BUFFER_CONDITION 19],
						[MTK_LCM_INPUT_TYPE_HEX_CURRENT_MODE 04],
						[C3 CC CC CC CC C0 FE 00 FE 00],
						[FE 00 FE 00 FE 00 FE 00 FE 00],
						[FE 00 FE],

					/* fhd 60 init*/
					[MTK_LCM_CMD_TYPE_HEX_WRITE_BUFFER_CONDITION 04],
						[MTK_LCM_INPUT_TYPE_HEX_CURRENT_MODE 05 C3 89],
					[MTK_LCM_CMD_TYPE_HEX_WRITE_BUFFER_CONDITION 06],
						[MTK_LCM_INPUT_TYPE_HEX_CURRENT_MODE 05],
						[B0 00 24 C3],
					[MTK_LCM_CMD_TYPE_HEX_WRITE_BUFFER_CONDITION 14],
						[MTK_LCM_INPUT_TYPE_HEX_CURRENT_MODE 05],
						[C3 FD 00 FD 00 FD 00 FD 00 FD],
						[00 FD 00 FD 00 FD 00 FD],
					[MTK_LCM_CMD_TYPE_HEX_WRITE_BUFFER_CONDITION 06],
						[MTK_LCM_INPUT_TYPE_HEX_CURRENT_MODE 05],
						[B0 00 3A C3],
					[MTK_LCM_CMD_TYPE_HEX_WRITE_BUFFER_CONDITION 14],
						[MTK_LCM_INPUT_TYPE_HEX_CURRENT_MODE 05],
						[C3 B0 00 B0 00 B0 00 B0 00 B0],
						[00 B0 00 B0 00 B0 00 B0],
					[MTK_LCM_CMD_TYPE_HEX_WRITE_BUFFER_CONDITION 06],
						[MTK_LCM_INPUT_TYPE_HEX_CURRENT_MODE 05],
						[B0 00 50 C3],
					[MTK_LCM_CMD_TYPE_HEX_WRITE_BUFFER_CONDITION 14],
						[MTK_LCM_INPUT_TYPE_HEX_CURRENT_MODE 05],
						[C3 43 00 43 00 43 00 43 00 43],
						[00 43 00 43 00 43 00 43],
					[MTK_LCM_CMD_TYPE_HEX_WRITE_BUFFER_CONDITION 06],
						[MTK_LCM_INPUT_TYPE_HEX_CURRENT_MODE 05],
						[B0 00 61 C3],
					[MTK_LCM_CMD_TYPE_HEX_WRITE_BUFFER_CONDITION 19],
						[MTK_LCM_INPUT_TYPE_HEX_CURRENT_MODE 05],
						[C3 CC CC CC CC C0 FE 00 FE 00],
						[FE 00 FE 00 FE 00 FE 00 FE 00],
						[FE 00 FE],
					[MTK_LCM_PHASE_TYPE_HEX_END 01 MTK_LCM_PHASE_HEX_KERNEL],

					[MTK_LCM_PHASE_TYPE_HEX_START 02 MTK_LCM_PHASE_HEX_LK],
						[MTK_LCM_PHASE_HEX_LK_DISPLAY_ON_DELAY],
					[MTK_LCM_CMD_TYPE_HEX_WRITE_BUFFER 02 C3 00],
					[MTK_LCM_PHASE_TYPE_HEX_END 02 MTK_LCM_PHASE_HEX_LK],
						[MTK_LCM_PHASE_HEX_LK_DISPLAY_ON_DELAY],

					[MTK_LCM_CMD_TYPE_HEX_WRITE_BUFFER 03],
							[F0 A5 A5],

	/* Pre-charge time setting */
					[MTK_LCM_CMD_TYPE_HEX_WRITE_BUFFER 03],
							[F0 5A 5A],
					[MTK_LCM_CMD_TYPE_HEX_WRITE_BUFFER 04],
							[B0 00 2B F6],
					[MTK_LCM_CMD_TYPE_HEX_WRITE_BUFFER 04],
							[F6 60 63 69],
					[MTK_LCM_CMD_TYPE_HEX_WRITE_BUFFER 02],
							[F7 0F],
					[MTK_LCM_CMD_TYPE_HEX_WRITE_BUFFER 03],
							[F0 A5 A5],

	/* HLPM Power Saving */
					[MTK_LCM_CMD_TYPE_HEX_WRITE_BUFFER 03],
							[F0 5A 5A],
					[MTK_LCM_CMD_TYPE_HEX_WRITE_BUFFER 04],
							[B0 00 46 F4],
					[MTK_LCM_CMD_TYPE_HEX_WRITE_BUFFER 02],
							[F4 08],
					[MTK_LCM_CMD_TYPE_HEX_WRITE_BUFFER 03],
							[F0 A5 A5],
					[MTK_LCM_CMD_TYPE_HEX_WRITE_BUFFER 03],
							[F0 5A 5A],
					[MTK_LCM_CMD_TYPE_HEX_WRITE_BUFFER 04],
							[B0 00 18 B1],
					[MTK_LCM_CMD_TYPE_HEX_WRITE_BUFFER 02],
							[B1 05],
					[MTK_LCM_CMD_TYPE_HEX_WRITE_BUFFER 03],
							[F0 A5 A5],

	/* Brightness Control */
					[MTK_LCM_CMD_TYPE_HEX_WRITE_BUFFER 03],
							[F0 5A 5A],
					[MTK_LCM_CMD_TYPE_HEX_WRITE_BUFFER 04],
							[B0 00 0D 63],
	/* Dimming Setting */
					[MTK_LCM_CMD_TYPE_HEX_WRITE_BUFFER 02],
							[63 01],
					[MTK_LCM_CMD_TYPE_HEX_WRITE_BUFFER 04],
							[B0 00 0C 63],
					[MTK_LCM_PHASE_TYPE_HEX_START 01 MTK_LCM_PHASE_HEX_KERNEL],
					[MTK_LCM_CMD_TYPE_HEX_WRITE_BUFFER 02],
							[63 20],
					[MTK_LCM_PHASE_TYPE_HEX_END 01 MTK_LCM_PHASE_HEX_KERNEL],

					[MTK_LCM_PHASE_TYPE_HEX_START 02 MTK_LCM_PHASE_HEX_LK],
						[MTK_LCM_PHASE_HEX_LK_DISPLAY_ON_DELAY],
					[MTK_LCM_CMD_TYPE_HEX_WRITE_BUFFER 02],
							[63 00],
					[MTK_LCM_PHASE_TYPE_HEX_END 02 MTK_LCM_PHASE_HEX_LK],
						[MTK_LCM_PHASE_HEX_LK_DISPLAY_ON_DELAY],
					[MTK_LCM_CMD_TYPE_HEX_WRITE_BUFFER 03],
							[F0 A5 A5],
					[MTK_LCM_CMD_TYPE_HEX_WRITE_BUFFER 02],
							[53 28],
					[MTK_LCM_CMD_TYPE_HEX_WRITE_BUFFER 02],
							[F7 0F],

	/* OPLUS ADFR On */
					[MTK_LCM_PHASE_TYPE_HEX_START 01 MTK_LCM_PHASE_HEX_KERNEL],
					[MTK_LCM_CMD_TYPE_HEX_WRITE_BUFFER 03],
						[F0 5A 5A],
					[MTK_LCM_CMD_TYPE_HEX_WRITE_BUFFER 03],
						[FC 5A 5A],
					[MTK_LCM_CMD_TYPE_HEX_WRITE_BUFFER 02 B9 02],
					[MTK_LCM_CMD_TYPE_HEX_WRITE_BUFFER 02 FD 4A],
					[MTK_LCM_CMD_TYPE_HEX_WRITE_BUFFER 04],
						[B0 00 18 F2],
					[MTK_LCM_CMD_TYPE_HEX_WRITE_BUFFER 03],
						[F2 1B 50],
					[MTK_LCM_CMD_TYPE_HEX_WRITE_BUFFER 04],
						[B0 00 74 BD],
					[MTK_LCM_CMD_TYPE_HEX_WRITE_BUFFER 02 BD 78],
					[MTK_LCM_CMD_TYPE_HEX_WRITE_BUFFER 03],
						[F2 01 00],
					[MTK_LCM_CMD_TYPE_HEX_WRITE_BUFFER 02 60 08],
					[MTK_LCM_CMD_TYPE_HEX_WRITE_BUFFER 04],
						[B0 00 10 F6],
					[MTK_LCM_CMD_TYPE_HEX_WRITE_BUFFER 02 F6 AA],
					[MTK_LCM_CMD_TYPE_HEX_WRITE_BUFFER 04],
						[B0 00 3F F6],
					[MTK_LCM_CMD_TYPE_HEX_WRITE_BUFFER 02 F6 1F],
					[MTK_LCM_CMD_TYPE_HEX_WRITE_BUFFER 04],
						[B0 00 45 F6],
					[MTK_LCM_CMD_TYPE_HEX_WRITE_BUFFER 02 F6 1F],
					[MTK_LCM_CMD_TYPE_HEX_WRITE_BUFFER 04],
						[B0 00 6C BD],
					[MTK_LCM_CMD_TYPE_HEX_WRITE_BUFFER 02 BD 80],
					[MTK_LCM_CMD_TYPE_HEX_WRITE_BUFFER 04],
						[B0 00 6F BD],
					[MTK_LCM_CMD_TYPE_HEX_WRITE_BUFFER 05],
						[BD 45 65 65 65],
					[MTK_LCM_CMD_TYPE_HEX_WRITE_BUFFER 04],
						[B0 00 06 60],
					[MTK_LCM_CMD_TYPE_HEX_WRITE_BUFFER 05],
						[60 00 00 00 00],
					[MTK_LCM_CMD_TYPE_HEX_WRITE_BUFFER 04],
						[B0 00 0A 60],
					[MTK_LCM_CMD_TYPE_HEX_WRITE_BUFFER 05],
						[60 00 00 00 00],
					[MTK_LCM_CMD_TYPE_HEX_WRITE_BUFFER 04],
						[B0 00 0E 60],
					[MTK_LCM_CMD_TYPE_HEX_WRITE_BUFFER 05],
						[60 FF 00 00 00],
					[MTK_LCM_CMD_TYPE_HEX_WRITE_BUFFER 04],
						[B0 00 13 60],
					[MTK_LCM_CMD_TYPE_HEX_WRITE_BUFFER 05],
						[60 FF 00 00 00],
					[MTK_LCM_CMD_TYPE_HEX_WRITE_BUFFER 04],
						[B0 00 18 60],
	/* oplus adfr -> max:min */
					/* wqhd 120 init*/
					[MTK_LCM_CMD_TYPE_HEX_WRITE_BUFFER_CONDITION 05],
						[MTK_LCM_INPUT_TYPE_HEX_CURRENT_MODE 00 06 00 00],
					/* wqhd 90 init*/
					[MTK_LCM_CMD_TYPE_HEX_WRITE_BUFFER_CONDITION 05],
						[MTK_LCM_INPUT_TYPE_HEX_CURRENT_MODE 01 06 04 01],
					/* wqhd 72 init*/
					[MTK_LCM_CMD_TYPE_HEX_WRITE_BUFFER_CONDITION 05],
						[MTK_LCM_INPUT_TYPE_HEX_CURRENT_MODE 02 06 08 02],
					/* wqhd 60 init*/
					[MTK_LCM_CMD_TYPE_HEX_WRITE_BUFFER_CONDITION 05],
						[MTK_LCM_INPUT_TYPE_HEX_CURRENT_MODE 03 06 0c 03],
					/* fhd 120 init*/
					[MTK_LCM_CMD_TYPE_HEX_WRITE_BUFFER_CONDITION 05],
						[MTK_LCM_INPUT_TYPE_HEX_CURRENT_MODE 04 06 00 00],
					/* fhd 60 init*/
					[MTK_LCM_CMD_TYPE_HEX_WRITE_BUFFER_CONDITION 05],
						[MTK_LCM_INPUT_TYPE_HEX_CURRENT_MODE 05 06 0c 03],

					[MTK_LCM_CMD_TYPE_HEX_WRITE_BUFFER 04],
						[B0 00 04 60],
					[MTK_LCM_CMD_TYPE_HEX_WRITE_BUFFER 03],
						[60 00 00],
					[MTK_LCM_CMD_TYPE_HEX_WRITE_BUFFER 04],
						[B0 00 02 60],
					[MTK_LCM_CMD_TYPE_HEX_WRITE_BUFFER 02 60 1C],
	/* Frame Compensation 82:off 02:on */
					[MTK_LCM_CMD_TYPE_HEX_WRITE_BUFFER 03],
						[BD 21 82],
					[MTK_LCM_CMD_TYPE_HEX_WRITE_BUFFER 02 F7 0F],
					[MTK_LCM_CMD_TYPE_HEX_WRITE_BUFFER 03],
						[FC A5 A5],
					[MTK_LCM_CMD_TYPE_HEX_WRITE_BUFFER 03],
						[F0 A5 A5],
					[MTK_LCM_PHASE_TYPE_HEX_END 01 MTK_LCM_PHASE_HEX_KERNEL],

	/* ACL Mode */
					[MTK_LCM_CMD_TYPE_HEX_WRITE_BUFFER 03],
							[F0 5A 5A],
					[MTK_LCM_CMD_TYPE_HEX_WRITE_BUFFER 02],
							[55 00],
					[MTK_LCM_CMD_TYPE_HEX_WRITE_BUFFER 03],
							[F0 A5 A5],

	/* OPEC Setting */
					[MTK_LCM_CMD_TYPE_HEX_WRITE_BUFFER 03],
							[F0 5A 5A],
					[MTK_LCM_CMD_TYPE_HEX_WRITE_BUFFER 04],
							[B0 00 56 1F],
					[MTK_LCM_CMD_TYPE_HEX_WRITE_BUFFER 11],
						[1F 01 17 01 18 06 88 06 89 0A],
						[E2 0A E3 11 F5 1B C0],
					[MTK_LCM_CMD_TYPE_HEX_WRITE_BUFFER 04],
							[B0 00 6A 1F],
					[MTK_LCM_CMD_TYPE_HEX_WRITE_BUFFER 1d],
						[1F 01 17 03 44 04 5A 05 71 06],
						[88 07 9E 08 B5 09 CB 0A E2 0B],
						[F9 0D 0F 0E 26 0F 3C 10 53],
					[MTK_LCM_CMD_TYPE_HEX_WRITE_BUFFER 04],
							[B0 00 52 1F],
					[MTK_LCM_CMD_TYPE_HEX_WRITE_BUFFER 02],
							[1F 02],
					[MTK_LCM_CMD_TYPE_HEX_WRITE_BUFFER 04],
							[B0 00 54 1F],
					[MTK_LCM_CMD_TYPE_HEX_WRITE_BUFFER 02],
							[1F 00],
					[MTK_LCM_CMD_TYPE_HEX_WRITE_BUFFER 03],
							[F0 A5 A5],
					[MTK_LCM_PHASE_TYPE_HEX_START 01 MTK_LCM_PHASE_HEX_KERNEL],
					[MTK_LCM_CMD_TYPE_HEX_WRITE_BUFFER_RUNTIME_INPUT 08],
						[MTK_LCM_INPUT_TYPE_HEX_CURRENT_BACKLIGHT 02 01 02],
						[03 51 03 ff],
					[MTK_LCM_PHASE_TYPE_HEX_END 01 MTK_LCM_PHASE_HEX_KERNEL],
					[MTK_LCM_PHASE_TYPE_HEX_START 02 MTK_LCM_PHASE_HEX_LK],
						[MTK_LCM_PHASE_HEX_LK_DISPLAY_ON_DELAY],
					[MTK_LCM_CMD_TYPE_HEX_WRITE_BUFFER 03],
							[51 07 ff],
					[MTK_LCM_PHASE_TYPE_HEX_END 02 MTK_LCM_PHASE_HEX_LK],
						[MTK_LCM_PHASE_HEX_LK_DISPLAY_ON_DELAY],
    /* Display On Setting */
					[MTK_LCM_PHASE_TYPE_HEX_START 02],
						[MTK_LCM_PHASE_HEX_LK],
						[MTK_LCM_PHASE_HEX_KERNEL],
					[MTK_LCM_CMD_TYPE_HEX_WRITE_BUFFER 01 29],
					[MTK_LCM_PHASE_TYPE_HEX_END 02],
						[MTK_LCM_PHASE_HEX_LK],
						[MTK_LCM_PHASE_HEX_KERNEL],
					[MTK_LCM_TYPE_HEX_END];

				unprepare-table = [MTK_LCM_CMD_TYPE_HEX_WRITE_BUFFER 01 28],
					[MTK_LCM_CMD_TYPE_HEX_WRITE_BUFFER 01 10],
					[MTK_LCM_UTIL_TYPE_HEX_MDELAY 01 78],
					[MTK_LCM_CMD_TYPE_HEX_WRITE_BUFFER 02 4f 01],
					[MTK_LCM_UTIL_TYPE_HEX_MDELAY 01 78],
					[MTK_LCM_TYPE_HEX_END];

				set-display-on-table =
					[MTK_LCM_PHASE_TYPE_HEX_START 02],
						[MTK_LCM_PHASE_HEX_LK],
						[MTK_LCM_PHASE_HEX_LK_DISPLAY_ON_DELAY],
					[MTK_LCM_UTIL_TYPE_HEX_TDELAY 01 c8],
					[MTK_LCM_CMD_TYPE_HEX_WRITE_BUFFER 01 29],
					[MTK_LCM_PHASE_TYPE_HEX_END 02],
						[MTK_LCM_PHASE_HEX_LK],
						[MTK_LCM_PHASE_HEX_LK_DISPLAY_ON_DELAY],
					[MTK_LCM_TYPE_HEX_END];

				lcm-update-table = [MTK_LCM_LK_TYPE_HEX_PREPARE_PARAM_COUNT 01 03],
						[MTK_LCM_LK_TYPE_HEX_PREPARE_PARAM 05],
						[00 00 05 39 02],
					/*2a is of data[1] bit0 */
					[MTK_LCM_LK_TYPE_HEX_PREPARE_PARAM_FIX_BIT 03 01 00 2a],
					/*x0-msb is of data[1] bit8 */
					[MTK_LCM_LK_TYPE_HEX_PREPARE_PARAM_X0_MSB_BIT 03 01 08 00],
					/*x0-lsb is of data[1] bit16 */
					[MTK_LCM_LK_TYPE_HEX_PREPARE_PARAM_X0_LSB_BIT 03 01 10 00],
					/*x1-msb is of data[1] bit24 */
					[MTK_LCM_LK_TYPE_HEX_PREPARE_PARAM_X1_MSB_BIT 03 01 18 00],
					/*x0-lsb is of data[2] bit0 */
					[MTK_LCM_LK_TYPE_HEX_PREPARE_PARAM_X1_LSB_BIT 03 02 00 00],
					[MTK_LCM_LK_TYPE_HEX_WRITE_PARAM 00],
					[MTK_LCM_LK_TYPE_HEX_PREPARE_PARAM_COUNT 01 03],
					[MTK_LCM_LK_TYPE_HEX_PREPARE_PARAM 05],
						[00 00 05 39 02],
					/*2b is of data[1] bit0 */
					[MTK_LCM_LK_TYPE_HEX_PREPARE_PARAM_FIX_BIT 03 01 00 2b],
					/*y0-msb is of data[1] bit8 */
					[MTK_LCM_LK_TYPE_HEX_PREPARE_PARAM_Y0_MSB_BIT 03 01 08 00],
					/*y0-lsb is of data[1] bit16 */
					[MTK_LCM_LK_TYPE_HEX_PREPARE_PARAM_Y0_LSB_BIT 03 01 10 00],
					/*y1-msb is of data[1] bit24 */
					[MTK_LCM_LK_TYPE_HEX_PREPARE_PARAM_Y1_MSB_BIT 03 01 18 00],
					/*y0-lsb is of data[2] bit0 */
					[MTK_LCM_LK_TYPE_HEX_PREPARE_PARAM_Y1_LSB_BIT 03 02 00 00],
					[MTK_LCM_LK_TYPE_HEX_WRITE_PARAM 00],
					[MTK_LCM_LK_TYPE_HEX_PREPARE_PARAM_COUNT 01 01],
					[MTK_LCM_LK_TYPE_HEX_PREPARE_PARAM 05],
						[00 00 2c 39 09],
					[MTK_LCM_LK_TYPE_HEX_WRITE_PARAM_UNFORCE 00],
					[MTK_LCM_TYPE_HEX_END];

				set-backlight-mask = <0x3ff>;
				set-backlight-cmdq-table =
					/* runtime input count, data id*/
					[MTK_LCM_CMD_TYPE_HEX_WRITE_BUFFER_RUNTIME_INPUT 08],
						[MTK_LCM_INPUT_TYPE_HEX_CURRENT_BACKLIGHT 02 01 02],
						[03 51 03 ff],
					[MTK_LCM_TYPE_HEX_END];

				set-aod-light-mask = <0x7ff>;
				set-aod-light-table;

				ata-id-value-data = [00 80 00];
				ata-check-table =
					[MTK_LCM_CMD_TYPE_HEX_READ_CMD 03 00 03 04],
					[MTK_LCM_TYPE_HEX_END];

				compare-id-value-data = [c5 c5];
				compare-id-table = [MTK_LCM_UTIL_TYPE_HEX_RESET 01 01],
					[MTK_LCM_UTIL_TYPE_HEX_MDELAY 01 0a],
					[MTK_LCM_UTIL_TYPE_HEX_RESET 01 00],
					[MTK_LCM_UTIL_TYPE_HEX_MDELAY 01 0a],
					[MTK_LCM_UTIL_TYPE_HEX_RESET 01 01],
					[MTK_LCM_UTIL_TYPE_HEX_MDELAY 01 0a],
					[MTK_LCM_LK_TYPE_HEX_PREPARE_PARAM_COUNT 01 01],
					[MTK_LCM_LK_TYPE_HEX_PREPARE_PARAM 05 00 00 01 37 00],
					[MTK_LCM_LK_TYPE_HEX_WRITE_PARAM 00],
					[MTK_LCM_CMD_TYPE_HEX_READ_CMD 03 00 02 da],
					[MTK_LCM_TYPE_HEX_END];

				doze-enable-start-table =
					[MTK_LCM_CMD_TYPE_HEX_WRITE_BUFFER 03],
							[f0 5a 5a],
					[MTK_LCM_CMD_TYPE_HEX_WRITE_BUFFER 02],
							[53 24],
					[MTK_LCM_CMD_TYPE_HEX_WRITE_BUFFER 03],
							[f0 a5 a5],
					[MTK_LCM_UTIL_TYPE_HEX_MDELAY 01 50],
					[MTK_LCM_CMD_TYPE_HEX_WRITE_BUFFER 01 29],
					[MTK_LCM_TYPE_HEX_END];

				doze-enable-table;

				doze-disable-table =
					[MTK_LCM_CMD_TYPE_HEX_WRITE_BUFFER 03],
							[f0 5a 5a],
					[MTK_LCM_CMD_TYPE_HEX_WRITE_BUFFER 02],
							[53 28],
					[MTK_LCM_CMD_TYPE_HEX_WRITE_BUFFER 03],
							[f0 a5 a5],
					[MTK_LCM_TYPE_HEX_END];

				doze-area-table;

				doze-post-disp-on-table;

				hbm-set-cmdq-switch-id;
				hbm-set-cmdq-switch-on;
				hbm-set-cmdq-switch-off;
				hbm-set-cmdq-table;

				gpio-test-table = [MTK_LCM_GPIO_TYPE_HEX_MODE 02 01 02],
					[MTK_LCM_GPIO_TYPE_HEX_DIR_OUTPUT 02 01 01],
					[MTK_LCM_GPIO_TYPE_HEX_OUT 02 01 01],
					[MTK_LCM_TYPE_HEX_END];

				msync-close-mte-default-table =
					[MTK_LCM_CMD_TYPE_HEX_WRITE_BUFFER 03],
						[F0 5A 5A],
					[MTK_LCM_CMD_TYPE_HEX_WRITE_BUFFER 02],
						[35 00],
					[MTK_LCM_CMD_TYPE_HEX_WRITE_BUFFER 02],
						[B9 02],
					[MTK_LCM_CMD_TYPE_HEX_WRITE_BUFFER 03],
						[F0 A5 A5],
					[MTK_LCM_TYPE_HEX_END];

				msync-default-mte-table =
		/* CASET/PASET Setting */
					[MTK_LCM_CMD_TYPE_HEX_WRITE_BUFFER 05],
						[2A 00 00 05 9F],
					[MTK_LCM_CMD_TYPE_HEX_WRITE_BUFFER 05],
						[2B 00 00 0C 8F],
					[MTK_LCM_CMD_TYPE_HEX_WRITE_BUFFER 03],

		/* Scaler Setting */
						[F0 5A 5A],
					[MTK_LCM_CMD_TYPE_HEX_WRITE_BUFFER 02],
						[C3 00],
					[MTK_LCM_CMD_TYPE_HEX_WRITE_BUFFER 03],
						[F0 A5 A5],
					[MTK_LCM_CMD_TYPE_HEX_WRITE_BUFFER 03],

		/* TSP_SYNC1 Fixed Setting */
						[F0 5A 5A],
					[MTK_LCM_CMD_TYPE_HEX_WRITE_BUFFER 04],
						[B0 00 22 B9],
					[MTK_LCM_CMD_TYPE_HEX_WRITE_BUFFER 03],
						[B9 A1 B1],
					[MTK_LCM_CMD_TYPE_HEX_WRITE_BUFFER 04],
						[B0 00 3A B9],
		/*  TSP_VSYNC Fixed TE 02:120 03:90 05:60 */
					[MTK_LCM_CMD_TYPE_HEX_WRITE_BUFFER 02],
						[B9 02],
					[MTK_LCM_CMD_TYPE_HEX_WRITE_BUFFER 04],
						[B0 00 26 B9],
					[MTK_LCM_CMD_TYPE_HEX_WRITE_BUFFER 03],
						[B9 00 00],
					[MTK_LCM_CMD_TYPE_HEX_WRITE_BUFFER 02],
						[F7 0F],
					[MTK_LCM_CMD_TYPE_HEX_WRITE_BUFFER 03],
						[F0 A5 A5],
					[MTK_LCM_CMD_TYPE_HEX_WRITE_BUFFER 03],

		/* TSP_SYNC3 Fixed Setting */
						[F0 5A 5A],
					[MTK_LCM_CMD_TYPE_HEX_WRITE_BUFFER 04],
						[B0 00 24 B9],
					[MTK_LCM_CMD_TYPE_HEX_WRITE_BUFFER 02],
						[B9 21],
					[MTK_LCM_CMD_TYPE_HEX_WRITE_BUFFER 04],
						[B0 00 38 B9],
		/* TSP_VSYNC Fixed TE 02:120 03:90 05:60 */
					[MTK_LCM_CMD_TYPE_HEX_WRITE_BUFFER 02],
						[B9 02],
					[MTK_LCM_CMD_TYPE_HEX_WRITE_BUFFER 04],
						[B0 00 2A B9],
					[MTK_LCM_CMD_TYPE_HEX_WRITE_BUFFER 03],
						[B9 00 00],
					[MTK_LCM_CMD_TYPE_HEX_WRITE_BUFFER 02],
						[F7 0F],
					[MTK_LCM_CMD_TYPE_HEX_WRITE_BUFFER 03],
						[F0 A5 A5],

		/* OPLUS ADFR On */
					[MTK_LCM_CMD_TYPE_HEX_WRITE_BUFFER 03],
						[F0 5A 5A],
					[MTK_LCM_CMD_TYPE_HEX_WRITE_BUFFER 03],
						[FC 5A 5A],
					[MTK_LCM_CMD_TYPE_HEX_WRITE_BUFFER 02],
						[B9 02],
					[MTK_LCM_CMD_TYPE_HEX_WRITE_BUFFER 02],
						[FD 4A],
					[MTK_LCM_CMD_TYPE_HEX_WRITE_BUFFER 04],
						[B0 00 18 F2],
					[MTK_LCM_CMD_TYPE_HEX_WRITE_BUFFER 03],
						[F2 1B 50],
					[MTK_LCM_CMD_TYPE_HEX_WRITE_BUFFER 04],
						[B0 00 74 BD],
					[MTK_LCM_CMD_TYPE_HEX_WRITE_BUFFER 02],
						[BD 78],
					[MTK_LCM_CMD_TYPE_HEX_WRITE_BUFFER 03],
						[F2 01 00],
					[MTK_LCM_CMD_TYPE_HEX_WRITE_BUFFER 02],
						[60 08],
					[MTK_LCM_CMD_TYPE_HEX_WRITE_BUFFER 04],
						[B0 00 10 F6],
					[MTK_LCM_CMD_TYPE_HEX_WRITE_BUFFER 02],
						[F6 AA],
					[MTK_LCM_CMD_TYPE_HEX_WRITE_BUFFER 04],
						[B0 00 3F F6],
					[MTK_LCM_CMD_TYPE_HEX_WRITE_BUFFER 02],
						[F6 1F],
					[MTK_LCM_CMD_TYPE_HEX_WRITE_BUFFER 04],
						[B0 00 45 F6],
					[MTK_LCM_CMD_TYPE_HEX_WRITE_BUFFER 02],
						[F6 1F],
					[MTK_LCM_CMD_TYPE_HEX_WRITE_BUFFER 04],
						[B0 00 6C BD],
					[MTK_LCM_CMD_TYPE_HEX_WRITE_BUFFER 02],
						[BD 80],
					[MTK_LCM_CMD_TYPE_HEX_WRITE_BUFFER 04],
						[B0 00 6F BD],
					[MTK_LCM_CMD_TYPE_HEX_WRITE_BUFFER 05],
						[BD 45 65 65 65],
					[MTK_LCM_CMD_TYPE_HEX_WRITE_BUFFER 04],
						[B0 00 06 60],
					[MTK_LCM_CMD_TYPE_HEX_WRITE_BUFFER 05],
						[60 00 00 00 00],
					[MTK_LCM_CMD_TYPE_HEX_WRITE_BUFFER 04],
						[B0 00 0A 60],
					[MTK_LCM_CMD_TYPE_HEX_WRITE_BUFFER 05],
						[60 00 00 00 00],
					[MTK_LCM_CMD_TYPE_HEX_WRITE_BUFFER 04],
						[B0 00 0E 60],
					[MTK_LCM_CMD_TYPE_HEX_WRITE_BUFFER 05],
						[60 FF 00 00 00],
					[MTK_LCM_CMD_TYPE_HEX_WRITE_BUFFER 04],
						[B0 00 13 60],
					[MTK_LCM_CMD_TYPE_HEX_WRITE_BUFFER 05],
						[60 FF 00 00 00],
					[MTK_LCM_CMD_TYPE_HEX_WRITE_BUFFER 04],
						[B0 00 18 60],
		/* oplus adfr -> max:min */
					[MTK_LCM_CMD_TYPE_HEX_WRITE_BUFFER 03],
						[60 00 00],
					[MTK_LCM_CMD_TYPE_HEX_WRITE_BUFFER 04],
						[B0 00 04 60],
					[MTK_LCM_CMD_TYPE_HEX_WRITE_BUFFER 03],
						[60 00 00],
					[MTK_LCM_CMD_TYPE_HEX_WRITE_BUFFER 04],
						[B0 00 02 60],
					[MTK_LCM_CMD_TYPE_HEX_WRITE_BUFFER 02],
						[60 1C],
		/* Frame Compensation 82:off 02:on */
					[MTK_LCM_CMD_TYPE_HEX_WRITE_BUFFER 03],
						[BD 21 82],
					[MTK_LCM_CMD_TYPE_HEX_WRITE_BUFFER 02],
						[F7 0F],
					[MTK_LCM_CMD_TYPE_HEX_WRITE_BUFFER 03],
						[FC A5 A5],
					[MTK_LCM_CMD_TYPE_HEX_WRITE_BUFFER 03],
						[F0 A5 A5],
					[MTK_LCM_TYPE_HEX_END];

				/* fps switch cmd for msync 2.0 feature */
				msync-switch-mte {
					compatible =
						"mediatek,lcm-ops-dsi-msync-switch-mte";

					msync-switch-mte-mode-list = [00 01 02 03];
					msync-switch-mte-default-table =
		/* CASET/PASET Setting */
						[MTK_LCM_CMD_TYPE_HEX_WRITE_BUFFER 05],
							[2A 00 00 05 9F],
						[MTK_LCM_CMD_TYPE_HEX_WRITE_BUFFER 05],
							[2B 00 00 0C 8F],

		/* Scaler Setting */
						[MTK_LCM_CMD_TYPE_HEX_WRITE_BUFFER 03],
							[F0 5A 5A],
						[MTK_LCM_CMD_TYPE_HEX_WRITE_BUFFER 02],
							[C3 00],
						[MTK_LCM_CMD_TYPE_HEX_WRITE_BUFFER 03],
							[F0 A5 A5],

		/* TSP_SYNC1 Fixed Setting */
						[MTK_LCM_CMD_TYPE_HEX_WRITE_BUFFER 03],
							[F0 5A 5A],
						[MTK_LCM_CMD_TYPE_HEX_WRITE_BUFFER 04],
							[B0 00 22 B9],
						[MTK_LCM_CMD_TYPE_HEX_WRITE_BUFFER 03],
							[B9 A1 B1],
						[MTK_LCM_CMD_TYPE_HEX_WRITE_BUFFER 04],
							[B0 00 3A B9],
		/*  TSP_VSYNC Fixed TE 02:120 03:90 05:60 */
						/*wqhd 120 msync switch mte*/
						[MTK_LCM_CMD_TYPE_HEX_WRITE_BUFFER_CONDITION 04],
						[MTK_LCM_INPUT_TYPE_HEX_CURRENT_MODE 00],
							[B9 02],
						/*wqhd 90 msync switch mte*/
						[MTK_LCM_CMD_TYPE_HEX_WRITE_BUFFER_CONDITION 04],
						[MTK_LCM_INPUT_TYPE_HEX_CURRENT_MODE 01],
							[B9 03],
						/*wqhd 72 msync switch mte*/
						[MTK_LCM_CMD_TYPE_HEX_WRITE_BUFFER_CONDITION 04],
						[MTK_LCM_INPUT_TYPE_HEX_CURRENT_MODE 02],
							[B9 04],
						/*wqhd 60 msync switch mte*/
						[MTK_LCM_CMD_TYPE_HEX_WRITE_BUFFER_CONDITION 04],
						[MTK_LCM_INPUT_TYPE_HEX_CURRENT_MODE 03],
							[B9 05],

						[MTK_LCM_CMD_TYPE_HEX_WRITE_BUFFER 04],
							[B0 00 26 B9],
						[MTK_LCM_CMD_TYPE_HEX_WRITE_BUFFER 03],
							[B9 00 00],
						[MTK_LCM_CMD_TYPE_HEX_WRITE_BUFFER 02],
							[F7 0F],
						[MTK_LCM_CMD_TYPE_HEX_WRITE_BUFFER 03],
							[F0 A5 A5],

		/* TSP_SYNC3 Fixed Setting */
						[MTK_LCM_CMD_TYPE_HEX_WRITE_BUFFER 03],
							[F0 5A 5A],
						[MTK_LCM_CMD_TYPE_HEX_WRITE_BUFFER 04],
							[B0 00 24 B9],
						[MTK_LCM_CMD_TYPE_HEX_WRITE_BUFFER 02],
							[B9 21],
						[MTK_LCM_CMD_TYPE_HEX_WRITE_BUFFER 04],
							[B0 00 38 B9],
		/* TSP_VSYNC Fixed TE 02:120 03:90 05:60 */
						/*wqhd 120 msync switch mte*/
						[MTK_LCM_CMD_TYPE_HEX_WRITE_BUFFER_CONDITION 04],
						[MTK_LCM_INPUT_TYPE_HEX_CURRENT_MODE 00],
							[B9 02],
						/*wqhd 90 msync switch mte*/
						[MTK_LCM_CMD_TYPE_HEX_WRITE_BUFFER_CONDITION 04],
						[MTK_LCM_INPUT_TYPE_HEX_CURRENT_MODE 01],
							[B9 03],
						/*wqhd 72 msync switch mte*/
						[MTK_LCM_CMD_TYPE_HEX_WRITE_BUFFER_CONDITION 04],
						[MTK_LCM_INPUT_TYPE_HEX_CURRENT_MODE 02],
							[B9 04],
						/*wqhd 60 msync switch mte*/
						[MTK_LCM_CMD_TYPE_HEX_WRITE_BUFFER_CONDITION 04],
						[MTK_LCM_INPUT_TYPE_HEX_CURRENT_MODE 03],
							[B9 05],

						[MTK_LCM_CMD_TYPE_HEX_WRITE_BUFFER 04],
							[B0 00 2A B9],
						[MTK_LCM_CMD_TYPE_HEX_WRITE_BUFFER 03],
							[B9 00 00],
						[MTK_LCM_CMD_TYPE_HEX_WRITE_BUFFER 02],
							[F7 0F],
						[MTK_LCM_CMD_TYPE_HEX_WRITE_BUFFER 03],
							[F0 A5 A5],

		/* OPLUS ADFR On */
						[MTK_LCM_CMD_TYPE_HEX_WRITE_BUFFER 03],
							[F0 5A 5A],
						[MTK_LCM_CMD_TYPE_HEX_WRITE_BUFFER 03],
							[FC 5A 5A],
						[MTK_LCM_CMD_TYPE_HEX_WRITE_BUFFER 02],
							[B9 02],
						[MTK_LCM_CMD_TYPE_HEX_WRITE_BUFFER 02],
							[FD 4A],
						[MTK_LCM_CMD_TYPE_HEX_WRITE_BUFFER 04],
							[B0 00 18 F2],
						[MTK_LCM_CMD_TYPE_HEX_WRITE_BUFFER 03],
							[F2 1B 50],
						[MTK_LCM_CMD_TYPE_HEX_WRITE_BUFFER 04],
							[B0 00 74 BD],
						[MTK_LCM_CMD_TYPE_HEX_WRITE_BUFFER 02],
							[BD 78],
						[MTK_LCM_CMD_TYPE_HEX_WRITE_BUFFER 03],
							[F2 01 00],
						[MTK_LCM_CMD_TYPE_HEX_WRITE_BUFFER 02],
							[60 08],
						[MTK_LCM_CMD_TYPE_HEX_WRITE_BUFFER 04],
							[B0 00 10 F6],
						[MTK_LCM_CMD_TYPE_HEX_WRITE_BUFFER 02],
							[F6 AA],
						[MTK_LCM_CMD_TYPE_HEX_WRITE_BUFFER 04],
							[B0 00 3F F6],
						[MTK_LCM_CMD_TYPE_HEX_WRITE_BUFFER 02],
							[F6 1F],
						[MTK_LCM_CMD_TYPE_HEX_WRITE_BUFFER 04],
							[B0 00 45 F6],
						[MTK_LCM_CMD_TYPE_HEX_WRITE_BUFFER 02],
							[F6 1F],
						[MTK_LCM_CMD_TYPE_HEX_WRITE_BUFFER 04],
							[B0 00 6C BD],
						[MTK_LCM_CMD_TYPE_HEX_WRITE_BUFFER 02],
							[BD 80],
						[MTK_LCM_CMD_TYPE_HEX_WRITE_BUFFER 04],
							[B0 00 6F BD],
						[MTK_LCM_CMD_TYPE_HEX_WRITE_BUFFER 05],
							[BD 45 65 65 65],
						[MTK_LCM_CMD_TYPE_HEX_WRITE_BUFFER 04],
							[B0 00 06 60],
						[MTK_LCM_CMD_TYPE_HEX_WRITE_BUFFER 05],
							[60 00 00 00 00],
						[MTK_LCM_CMD_TYPE_HEX_WRITE_BUFFER 04],
							[B0 00 0A 60],
						[MTK_LCM_CMD_TYPE_HEX_WRITE_BUFFER 05],
							[60 00 00 00 00],
						[MTK_LCM_CMD_TYPE_HEX_WRITE_BUFFER 04],
							[B0 00 0E 60],
						[MTK_LCM_CMD_TYPE_HEX_WRITE_BUFFER 05],
							[60 FF 00 00 00],
						[MTK_LCM_CMD_TYPE_HEX_WRITE_BUFFER 04],
							[B0 00 13 60],
						[MTK_LCM_CMD_TYPE_HEX_WRITE_BUFFER 05],
							[60 FF 00 00 00],
						[MTK_LCM_CMD_TYPE_HEX_WRITE_BUFFER 04],
							[B0 00 18 60],
		/* oplus adfr -> max:min */
						/*wqhd 120 msync switch mte*/
						[MTK_LCM_CMD_TYPE_HEX_WRITE_BUFFER_CONDITION 05],
						[MTK_LCM_INPUT_TYPE_HEX_CURRENT_MODE 00],
							[60 00 00],
						/*wqhd 90 msync switch mte*/
						[MTK_LCM_CMD_TYPE_HEX_WRITE_BUFFER_CONDITION 05],
						[MTK_LCM_INPUT_TYPE_HEX_CURRENT_MODE 01],
							[60 04 01],
						/*wqhd 72 msync switch mte*/
						[MTK_LCM_CMD_TYPE_HEX_WRITE_BUFFER_CONDITION 05],
						[MTK_LCM_INPUT_TYPE_HEX_CURRENT_MODE 02],
							[60 08 02],
						/*wqhd 60 msync switch mte*/
						[MTK_LCM_CMD_TYPE_HEX_WRITE_BUFFER_CONDITION 05],
						[MTK_LCM_INPUT_TYPE_HEX_CURRENT_MODE 03],
							[60 0C 03],

						[MTK_LCM_CMD_TYPE_HEX_WRITE_BUFFER 04],
							[B0 00 04 60],
						[MTK_LCM_CMD_TYPE_HEX_WRITE_BUFFER 03],
							[60 00 00],
						[MTK_LCM_CMD_TYPE_HEX_WRITE_BUFFER 04],
							[B0 00 02 60],
						[MTK_LCM_CMD_TYPE_HEX_WRITE_BUFFER 02],
							[60 1C],
		/* Frame Compensation 82:off 02:on */
						[MTK_LCM_CMD_TYPE_HEX_WRITE_BUFFER 03],
							[BD 21 82],
						[MTK_LCM_CMD_TYPE_HEX_WRITE_BUFFER 02],
							[F7 0F],
						[MTK_LCM_CMD_TYPE_HEX_WRITE_BUFFER 03],
							[FC A5 A5],
						[MTK_LCM_CMD_TYPE_HEX_WRITE_BUFFER 03],
							[F0 A5 A5],

		/* Open Multi-TE */
						[MTK_LCM_CMD_TYPE_HEX_WRITE_BUFFER 03],
							[F0 5A 5A],
						[MTK_LCM_CMD_TYPE_HEX_WRITE_BUFFER 02],
							[35 00],
						[MTK_LCM_CMD_TYPE_HEX_WRITE_BUFFER 02],
							[B9 0A],
						[MTK_LCM_CMD_TYPE_HEX_WRITE_BUFFER 03],
							[F0 A5 A5],

		/* Min FPS */
						[MTK_LCM_CMD_TYPE_HEX_WRITE_BUFFER 04],
							[B0 00 18 60],
						/*wqhd 120 msync switch mte*/
						[MTK_LCM_CMD_TYPE_HEX_WRITE_BUFFER_CONDITION 05],
						[MTK_LCM_INPUT_TYPE_HEX_CURRENT_MODE 00],
							[60 00 03],
						/*wqhd 90 msync switch mte*/
						[MTK_LCM_CMD_TYPE_HEX_WRITE_BUFFER_CONDITION 05],
						[MTK_LCM_INPUT_TYPE_HEX_CURRENT_MODE 01],
							[60 04 04],
						/*wqhd 72 msync switch mte*/
						[MTK_LCM_CMD_TYPE_HEX_WRITE_BUFFER_CONDITION 05],
						[MTK_LCM_INPUT_TYPE_HEX_CURRENT_MODE 02],
							[60 08 05],
						/*wqhd 60 msync switch mte*/
						[MTK_LCM_CMD_TYPE_HEX_WRITE_BUFFER_CONDITION 05],
						[MTK_LCM_INPUT_TYPE_HEX_CURRENT_MODE 03],
							[60 0C 06],
						[MTK_LCM_TYPE_HEX_END];
				};

				/* fps switch cmd for high frame rate feature */
				lcm-ops-dsi-fps-switch-after-poweron {
					compatible =
						"mediatek,lcm-ops-dsi-fps-switch-after-poweron";

					fps-switch-mode-list = [00 01 02 03 04 05];
					default-fps-switch-table =
		/* Dsc 10bit input */
					/*wqhd 120 mode switch*/
						[MTK_LCM_CMD_TYPE_HEX_WRITE_BUFFER_CONDITION 5c],
						[MTK_LCM_INPUT_TYPE_HEX_CURRENT_MODE 00 9E 11],
						[00 00 AB 30 80 0C 90 05 A0],
						[00 18 02 D0 02 D0 02 00 02],
						[86 00 20 02 83 00 0A 00 0D],
						[04 86 03 2E 18 00 10 F0 07],
						[10 20 00 06 0F 0F 33 0E 1C],
						[2A 38 46 54 62 69 70 77 79],
						[7B 7D 7E 02 02 22 00 2A 40],
						[2A BE 3A FC 3A FA 3A F8 3B],
						[38 3B 78 3B B6 4B B6 4B F4],
						[4B F4 6C 34 84 74 00],
					/*wqhd 90 mode switch*/
						[MTK_LCM_CMD_TYPE_HEX_WRITE_BUFFER_CONDITION 5c],
						[MTK_LCM_INPUT_TYPE_HEX_CURRENT_MODE 01 9E 11],
						[00 00 AB 30 80 0C 90 05 A0],
						[00 18 02 D0 02 D0 02 00 02],
						[86 00 20 02 83 00 0A 00 0D],
						[04 86 03 2E 18 00 10 F0 07],
						[10 20 00 06 0F 0F 33 0E 1C],
						[2A 38 46 54 62 69 70 77 79],
						[7B 7D 7E 02 02 22 00 2A 40],
						[2A BE 3A FC 3A FA 3A F8 3B],
						[38 3B 78 3B B6 4B B6 4B F4],
						[4B F4 6C 34 84 74 00],
					/*wqhd 72 mode switch*/
						[MTK_LCM_CMD_TYPE_HEX_WRITE_BUFFER_CONDITION 5c],
						[MTK_LCM_INPUT_TYPE_HEX_CURRENT_MODE 02 9E 11],
						[00 00 AB 30 80 0C 90 05 A0],
						[00 18 02 D0 02 D0 02 00 02],
						[86 00 20 02 83 00 0A 00 0D],
						[04 86 03 2E 18 00 10 F0 07],
						[10 20 00 06 0F 0F 33 0E 1C],
						[2A 38 46 54 62 69 70 77 79],
						[7B 7D 7E 02 02 22 00 2A 40],
						[2A BE 3A FC 3A FA 3A F8 3B],
						[38 3B 78 3B B6 4B B6 4B F4],
						[4B F4 6C 34 84 74 00],
					/*wqhd 60 mode switch*/
						[MTK_LCM_CMD_TYPE_HEX_WRITE_BUFFER_CONDITION 5c],
						[MTK_LCM_INPUT_TYPE_HEX_CURRENT_MODE 03 9E 11],
						[00 00 AB 30 80 0C 90 05 A0],
						[00 18 02 D0 02 D0 02 00 02],
						[86 00 20 02 83 00 0A 00 0D],
						[04 86 03 2E 18 00 10 F0 07],
						[10 20 00 06 0F 0F 33 0E 1C],
						[2A 38 46 54 62 69 70 77 79],
						[7B 7D 7E 02 02 22 00 2A 40],
						[2A BE 3A FC 3A FA 3A F8 3B],
						[38 3B 78 3B B6 4B B6 4B F4],
						[4B F4 6C 34 84 74 00],
					/*fhd 120 mode switch*/
						[MTK_LCM_CMD_TYPE_HEX_WRITE_BUFFER_CONDITION 5c],
						[MTK_LCM_INPUT_TYPE_HEX_CURRENT_MODE 04 9E 11],
						[00 00 AB 30 80 09 6C 04 38],
						[00 24 02 1C 02 1C 02 00 02],
						[3B 00 20 03 35 00 07 00 0E],
						[03 34 02 D4 18 00 10 F0 07],
						[10 20 00 06 0F 0F 33 0E 1C],
						[2A 38 46 54 62 69 70 77 79],
						[7B 7D 7E 02 02 22 00 2A 40],
						[2A BE 3A FC 3A FA 3A F8 3B],
						[38 3B 78 3B B6 4B B6 4B F4],
						[4B F4 6C 34 84 74 00],
					/*fhd 60 mode switch*/
						[MTK_LCM_CMD_TYPE_HEX_WRITE_BUFFER_CONDITION 5c],
						[MTK_LCM_INPUT_TYPE_HEX_CURRENT_MODE 05 9E 11],
						[00 00 AB 30 80 09 6C 04 38],
						[00 24 02 1C 02 1C 02 00 02],
						[3B 00 20 03 35 00 07 00 0E],
						[03 34 02 D4 18 00 10 F0 07],
						[10 20 00 06 0F 0F 33 0E 1C],
						[2A 38 46 54 62 69 70 77 79],
						[7B 7D 7E 02 02 22 00 2A 40],
						[2A BE 3A FC 3A FA 3A F8 3B],
						[38 3B 78 3B B6 4B B6 4B F4],
						[4B F4 6C 34 84 74 00],
						[MTK_LCM_CMD_TYPE_HEX_WRITE_BUFFER 02 9D 01],
		/* CASET/PASET Setting */
					/*wqhd 120 mode switch*/
						[MTK_LCM_CMD_TYPE_HEX_WRITE_BUFFER_CONDITION 07],
						[MTK_LCM_INPUT_TYPE_HEX_CURRENT_MODE 00],
							[2A 00 00 05 9F],
						[MTK_LCM_CMD_TYPE_HEX_WRITE_BUFFER_CONDITION 07],
						[MTK_LCM_INPUT_TYPE_HEX_CURRENT_MODE 00],
							[2B 00 00 0C 8F],
					/*wqhd 90 mode switch*/
						[MTK_LCM_CMD_TYPE_HEX_WRITE_BUFFER_CONDITION 07],
						[MTK_LCM_INPUT_TYPE_HEX_CURRENT_MODE 01],
							[2A 00 00 05 9F],
						[MTK_LCM_CMD_TYPE_HEX_WRITE_BUFFER_CONDITION 07],
						[MTK_LCM_INPUT_TYPE_HEX_CURRENT_MODE 01],
							[2B 00 00 0C 8F],
					/*wqhd 72 mode switch*/
						[MTK_LCM_CMD_TYPE_HEX_WRITE_BUFFER_CONDITION 07],
						[MTK_LCM_INPUT_TYPE_HEX_CURRENT_MODE 02],
							[2A 00 00 05 9F],
						[MTK_LCM_CMD_TYPE_HEX_WRITE_BUFFER_CONDITION 07],
						[MTK_LCM_INPUT_TYPE_HEX_CURRENT_MODE 02],
							[2B 00 00 0C 8F],
					/*wqhd 60 mode switch*/
						[MTK_LCM_CMD_TYPE_HEX_WRITE_BUFFER_CONDITION 07],
						[MTK_LCM_INPUT_TYPE_HEX_CURRENT_MODE 03],
							[2A 00 00 05 9F],
						[MTK_LCM_CMD_TYPE_HEX_WRITE_BUFFER_CONDITION 07],
						[MTK_LCM_INPUT_TYPE_HEX_CURRENT_MODE 03],
							[2B 00 00 0C 8F],
					/*fhd 120 mode switch*/
						[MTK_LCM_CMD_TYPE_HEX_WRITE_BUFFER_CONDITION 07],
						[MTK_LCM_INPUT_TYPE_HEX_CURRENT_MODE 04],
							[2A 00 00 04 37],
						[MTK_LCM_CMD_TYPE_HEX_WRITE_BUFFER_CONDITION 07],
						[MTK_LCM_INPUT_TYPE_HEX_CURRENT_MODE 04],
							[2B 00 00 09 6b],
					/*fhd 60 mode switch*/
						[MTK_LCM_CMD_TYPE_HEX_WRITE_BUFFER_CONDITION 07],
						[MTK_LCM_INPUT_TYPE_HEX_CURRENT_MODE 05],
							[2A 00 00 04 37],
						[MTK_LCM_CMD_TYPE_HEX_WRITE_BUFFER_CONDITION 07],
						[MTK_LCM_INPUT_TYPE_HEX_CURRENT_MODE 05],
							[2B 00 00 09 6b],
		/* Scaler Setting */
						[MTK_LCM_CMD_TYPE_HEX_WRITE_BUFFER 03],
							[F0 5A 5A],
					/*wqhd 120 mode switch*/
						[MTK_LCM_CMD_TYPE_HEX_WRITE_BUFFER_CONDITION 04],
						[MTK_LCM_INPUT_TYPE_HEX_CURRENT_MODE 00],
							[C3 00],
					/*wqhd 90 mode switch*/
						[MTK_LCM_CMD_TYPE_HEX_WRITE_BUFFER_CONDITION 04],
						[MTK_LCM_INPUT_TYPE_HEX_CURRENT_MODE 01],
							[C3 00],
					/*wqhd 72 mode switch*/
						[MTK_LCM_CMD_TYPE_HEX_WRITE_BUFFER_CONDITION 04],
						[MTK_LCM_INPUT_TYPE_HEX_CURRENT_MODE 02],
							[C3 00],
					/*wqhd 60 mode switch*/
						[MTK_LCM_CMD_TYPE_HEX_WRITE_BUFFER_CONDITION 04],
						[MTK_LCM_INPUT_TYPE_HEX_CURRENT_MODE 03],
							[C3 00],
					/*fhd 120 mode switch*/
						[MTK_LCM_CMD_TYPE_HEX_WRITE_BUFFER_CONDITION 04],
						[MTK_LCM_INPUT_TYPE_HEX_CURRENT_MODE 04],
							[C3 89],
						[MTK_LCM_CMD_TYPE_HEX_WRITE_BUFFER_CONDITION 06],
						[MTK_LCM_INPUT_TYPE_HEX_CURRENT_MODE 04],
							[B0 00 24 C3],
						[MTK_LCM_CMD_TYPE_HEX_WRITE_BUFFER_CONDITION 14],
						[MTK_LCM_INPUT_TYPE_HEX_CURRENT_MODE 04],
							[C3 FD 00 FD 00 FD 00 FD 00 FD],
							[00 FD 00 FD 00 FD 00 FD],
						[MTK_LCM_CMD_TYPE_HEX_WRITE_BUFFER_CONDITION 06],
						[MTK_LCM_INPUT_TYPE_HEX_CURRENT_MODE 04],
							[B0 00 3A C3],
						[MTK_LCM_CMD_TYPE_HEX_WRITE_BUFFER_CONDITION 14],
						[MTK_LCM_INPUT_TYPE_HEX_CURRENT_MODE 04],
							[C3 B0 00 B0 00 B0 00 B0 00 B0],
							[00 B0 00 B0 00 B0 00 B0],
						[MTK_LCM_CMD_TYPE_HEX_WRITE_BUFFER_CONDITION 06],
						[MTK_LCM_INPUT_TYPE_HEX_CURRENT_MODE 04],
							[B0 00 50 C3],
						[MTK_LCM_CMD_TYPE_HEX_WRITE_BUFFER_CONDITION 14],
						[MTK_LCM_INPUT_TYPE_HEX_CURRENT_MODE 04],
							[C3 43 00 43 00 43 00 43 00 43],
							[00 43 00 43 00 43 00 43],
						[MTK_LCM_CMD_TYPE_HEX_WRITE_BUFFER_CONDITION 06],
						[MTK_LCM_INPUT_TYPE_HEX_CURRENT_MODE 04],
							[B0 00 61 C3],
						[MTK_LCM_CMD_TYPE_HEX_WRITE_BUFFER_CONDITION 19],
						[MTK_LCM_INPUT_TYPE_HEX_CURRENT_MODE 04],
							[C3 CC CC CC CC C0 FE 00 FE 00],
							[FE 00 FE 00 FE 00 FE 00 FE 00],
							[FE 00 FE],
					/*fhd 60 mode switch*/
						[MTK_LCM_CMD_TYPE_HEX_WRITE_BUFFER_CONDITION 04],
						[MTK_LCM_INPUT_TYPE_HEX_CURRENT_MODE 05],
							[C3 89],
						[MTK_LCM_CMD_TYPE_HEX_WRITE_BUFFER_CONDITION 06],
						[MTK_LCM_INPUT_TYPE_HEX_CURRENT_MODE 05],
							[B0 00 24 C3],
						[MTK_LCM_CMD_TYPE_HEX_WRITE_BUFFER_CONDITION 14],
						[MTK_LCM_INPUT_TYPE_HEX_CURRENT_MODE 05],
							[C3 FD 00 FD 00 FD 00 FD 00 FD],
							[00 FD 00 FD 00 FD 00 FD],
						[MTK_LCM_CMD_TYPE_HEX_WRITE_BUFFER_CONDITION 06],
						[MTK_LCM_INPUT_TYPE_HEX_CURRENT_MODE 05],
							[B0 00 3A C3],
						[MTK_LCM_CMD_TYPE_HEX_WRITE_BUFFER_CONDITION 14],
						[MTK_LCM_INPUT_TYPE_HEX_CURRENT_MODE 05],
							[C3 B0 00 B0 00 B0 00 B0 00 B0],
							[00 B0 00 B0 00 B0 00 B0],
						[MTK_LCM_CMD_TYPE_HEX_WRITE_BUFFER_CONDITION 06],
						[MTK_LCM_INPUT_TYPE_HEX_CURRENT_MODE 05],
							[B0 00 50 C3],
						[MTK_LCM_CMD_TYPE_HEX_WRITE_BUFFER_CONDITION 14],
						[MTK_LCM_INPUT_TYPE_HEX_CURRENT_MODE 05],
							[C3 43 00 43 00 43 00 43 00 43],
							[00 43 00 43 00 43 00 43],
						[MTK_LCM_CMD_TYPE_HEX_WRITE_BUFFER_CONDITION 06],
						[MTK_LCM_INPUT_TYPE_HEX_CURRENT_MODE 05],
							[B0 00 61 C3],
						[MTK_LCM_CMD_TYPE_HEX_WRITE_BUFFER_CONDITION 19],
						[MTK_LCM_INPUT_TYPE_HEX_CURRENT_MODE 05],
							[C3 CC CC CC CC C0 FE 00 FE 00],
							[FE 00 FE 00 FE 00 FE 00 FE 00],
							[FE 00 FE],
						[MTK_LCM_CMD_TYPE_HEX_WRITE_BUFFER 03],
							[F0 A5 A5],

		/* TSP_SYNC1 Fixed Setting */
						[MTK_LCM_CMD_TYPE_HEX_WRITE_BUFFER 03],
							[F0 5A 5A],
						[MTK_LCM_CMD_TYPE_HEX_WRITE_BUFFER 04],
							[B0 00 22 B9],
						[MTK_LCM_CMD_TYPE_HEX_WRITE_BUFFER 03],
							[B9 A1 B1],
						[MTK_LCM_CMD_TYPE_HEX_WRITE_BUFFER 04],
							[B0 00 3A B9],
		/* TSP_VSYNC Fixed TE 02:120 03:90 05:60 */
					/*wqhd 120 mode switch*/
						[MTK_LCM_CMD_TYPE_HEX_WRITE_BUFFER_CONDITION 04],
						[MTK_LCM_INPUT_TYPE_HEX_CURRENT_MODE 00],
							[B9 02],
					/*wqhd 90 mode switch*/
						[MTK_LCM_CMD_TYPE_HEX_WRITE_BUFFER_CONDITION 04],
						[MTK_LCM_INPUT_TYPE_HEX_CURRENT_MODE 01],
							[B9 03],
					/*wqhd 72 mode switch*/
						[MTK_LCM_CMD_TYPE_HEX_WRITE_BUFFER_CONDITION 04],
						[MTK_LCM_INPUT_TYPE_HEX_CURRENT_MODE 02],
							[B9 04],
					/*wqhd 60 mode switch*/
						[MTK_LCM_CMD_TYPE_HEX_WRITE_BUFFER_CONDITION 04],
						[MTK_LCM_INPUT_TYPE_HEX_CURRENT_MODE 03],
							[B9 05],
					/*fhd 120 mode switch*/
						[MTK_LCM_CMD_TYPE_HEX_WRITE_BUFFER_CONDITION 04],
						[MTK_LCM_INPUT_TYPE_HEX_CURRENT_MODE 04],
							[B9 02],
					/*fhd 60 mode switch*/
						[MTK_LCM_CMD_TYPE_HEX_WRITE_BUFFER_CONDITION 04],
						[MTK_LCM_INPUT_TYPE_HEX_CURRENT_MODE 05],
							[B9 05],
						[MTK_LCM_CMD_TYPE_HEX_WRITE_BUFFER 04],
							[B0 00 26 B9],
						[MTK_LCM_CMD_TYPE_HEX_WRITE_BUFFER 03],
							[B9 00 00],
						[MTK_LCM_CMD_TYPE_HEX_WRITE_BUFFER 02],
							[F7 0F],
						[MTK_LCM_CMD_TYPE_HEX_WRITE_BUFFER 03],
							[F0 A5 A5],

		/* TSP_SYNC3 Fixed Setting */
						[MTK_LCM_CMD_TYPE_HEX_WRITE_BUFFER 03],
							[F0 5A 5A],
						[MTK_LCM_CMD_TYPE_HEX_WRITE_BUFFER 04],
							[B0 00 24 B9],
						[MTK_LCM_CMD_TYPE_HEX_WRITE_BUFFER 02],
							[B9 21],
						[MTK_LCM_CMD_TYPE_HEX_WRITE_BUFFER 04],
							[B0 00 38 B9],
		/* TSP_VSYNC Fixed TE 02:120 03:90 05:60 */
					/*wqhd 120 mode switch*/
						[MTK_LCM_CMD_TYPE_HEX_WRITE_BUFFER_CONDITION 04],
						[MTK_LCM_INPUT_TYPE_HEX_CURRENT_MODE 00],
							[B9 02],
					/*wqhd 90 mode switch*/
						[MTK_LCM_CMD_TYPE_HEX_WRITE_BUFFER_CONDITION 04],
						[MTK_LCM_INPUT_TYPE_HEX_CURRENT_MODE 01],
							[B9 03],
					/*wqhd 72 mode switch*/
						[MTK_LCM_CMD_TYPE_HEX_WRITE_BUFFER_CONDITION 04],
						[MTK_LCM_INPUT_TYPE_HEX_CURRENT_MODE 02],
							[B9 04],
					/*wqhd 60 mode switch*/
						[MTK_LCM_CMD_TYPE_HEX_WRITE_BUFFER_CONDITION 04],
						[MTK_LCM_INPUT_TYPE_HEX_CURRENT_MODE 03],
							[B9 05],
					/*fhd 120 mode switch*/
						[MTK_LCM_CMD_TYPE_HEX_WRITE_BUFFER_CONDITION 04],
						[MTK_LCM_INPUT_TYPE_HEX_CURRENT_MODE 04],
							[B9 02],
					/*fhd 60 mode switch*/
						[MTK_LCM_CMD_TYPE_HEX_WRITE_BUFFER_CONDITION 04],
						[MTK_LCM_INPUT_TYPE_HEX_CURRENT_MODE 05],
							[B9 05],
						[MTK_LCM_CMD_TYPE_HEX_WRITE_BUFFER 04],
							[B0 00 2A B9],
						[MTK_LCM_CMD_TYPE_HEX_WRITE_BUFFER 03],
							[B9 00 00],
						[MTK_LCM_CMD_TYPE_HEX_WRITE_BUFFER 02],
							[F7 0F],
						[MTK_LCM_CMD_TYPE_HEX_WRITE_BUFFER 03],
							[F0 A5 A5],

		/* OPLUS ADFR On */
						[MTK_LCM_CMD_TYPE_HEX_WRITE_BUFFER 03],
							[F0 5A 5A],
						[MTK_LCM_CMD_TYPE_HEX_WRITE_BUFFER 03],
							[FC 5A 5A],
						[MTK_LCM_CMD_TYPE_HEX_WRITE_BUFFER 02],
							[B9 02],
						[MTK_LCM_CMD_TYPE_HEX_WRITE_BUFFER 02],
							[FD 4A],
						[MTK_LCM_CMD_TYPE_HEX_WRITE_BUFFER 04],
							[B0 00 18 F2],
						[MTK_LCM_CMD_TYPE_HEX_WRITE_BUFFER 03],
							[F2 1B 50],
						[MTK_LCM_CMD_TYPE_HEX_WRITE_BUFFER 04],
							[B0 00 74 BD],
						[MTK_LCM_CMD_TYPE_HEX_WRITE_BUFFER 02],
							[BD 78],
						[MTK_LCM_CMD_TYPE_HEX_WRITE_BUFFER 03],
							[F2 01 00],
						[MTK_LCM_CMD_TYPE_HEX_WRITE_BUFFER 02],
							[60 08],
						[MTK_LCM_CMD_TYPE_HEX_WRITE_BUFFER 04],
							[B0 00 10 F6],
						[MTK_LCM_CMD_TYPE_HEX_WRITE_BUFFER 02],
							[F6 AA],
						[MTK_LCM_CMD_TYPE_HEX_WRITE_BUFFER 04],
							[B0 00 3F F6],
						[MTK_LCM_CMD_TYPE_HEX_WRITE_BUFFER 02],
							[F6 1F],
						[MTK_LCM_CMD_TYPE_HEX_WRITE_BUFFER 04],
							[B0 00 45 F6],
						[MTK_LCM_CMD_TYPE_HEX_WRITE_BUFFER 02],
							[F6 1F],
						[MTK_LCM_CMD_TYPE_HEX_WRITE_BUFFER 04],
							[B0 00 6C BD],
						[MTK_LCM_CMD_TYPE_HEX_WRITE_BUFFER 02],
							[BD 80],
						[MTK_LCM_CMD_TYPE_HEX_WRITE_BUFFER 04],
							[B0 00 6F BD],
						[MTK_LCM_CMD_TYPE_HEX_WRITE_BUFFER 05],
							[BD 45 65 65 65],
						[MTK_LCM_CMD_TYPE_HEX_WRITE_BUFFER 04],
							[B0 00 06 60],
						[MTK_LCM_CMD_TYPE_HEX_WRITE_BUFFER 05],
							[60 00 00 00 00],
						[MTK_LCM_CMD_TYPE_HEX_WRITE_BUFFER 04],
							[B0 00 0A 60],
						[MTK_LCM_CMD_TYPE_HEX_WRITE_BUFFER 05],
							[60 00 00 00 00],
						[MTK_LCM_CMD_TYPE_HEX_WRITE_BUFFER 04],
							[B0 00 0E 60],
						[MTK_LCM_CMD_TYPE_HEX_WRITE_BUFFER 05],
							[60 FF 00 00 00],
						[MTK_LCM_CMD_TYPE_HEX_WRITE_BUFFER 04],
							[B0 00 13 60],
						[MTK_LCM_CMD_TYPE_HEX_WRITE_BUFFER 05],
							[60 FF 00 00 00],
						[MTK_LCM_CMD_TYPE_HEX_WRITE_BUFFER 04],
							[B0 00 18 60],
		/* oplus adfr -> max:min */
					/*wqhd 120 mode switch*/
						[MTK_LCM_CMD_TYPE_HEX_WRITE_BUFFER_CONDITION 05],
						[MTK_LCM_INPUT_TYPE_HEX_CURRENT_MODE 00],
							[60 00 00],
					/*wqhd 90 mode switch*/
						[MTK_LCM_CMD_TYPE_HEX_WRITE_BUFFER_CONDITION 05],
						[MTK_LCM_INPUT_TYPE_HEX_CURRENT_MODE 01],
							[60 04 01],
					/*wqhd 72 mode switch*/
						[MTK_LCM_CMD_TYPE_HEX_WRITE_BUFFER_CONDITION 05],
						[MTK_LCM_INPUT_TYPE_HEX_CURRENT_MODE 02],
							[60 08 02],
					/*wqhd 60 mode switch*/
						[MTK_LCM_CMD_TYPE_HEX_WRITE_BUFFER_CONDITION 05],
						[MTK_LCM_INPUT_TYPE_HEX_CURRENT_MODE 03],
							[60 0C 03],
					/*fhd 120 mode switch*/
						[MTK_LCM_CMD_TYPE_HEX_WRITE_BUFFER_CONDITION 05],
						[MTK_LCM_INPUT_TYPE_HEX_CURRENT_MODE 04],
							[60 00 00],
					/*fhd 60 mode switch*/
						[MTK_LCM_CMD_TYPE_HEX_WRITE_BUFFER_CONDITION 05],
						[MTK_LCM_INPUT_TYPE_HEX_CURRENT_MODE 05],
							[60 0C 03],
						[MTK_LCM_CMD_TYPE_HEX_WRITE_BUFFER 04],
							[B0 00 04 60],
						[MTK_LCM_CMD_TYPE_HEX_WRITE_BUFFER 03],
							[60 00 00],
						[MTK_LCM_CMD_TYPE_HEX_WRITE_BUFFER 04],
							[B0 00 02 60],
						[MTK_LCM_CMD_TYPE_HEX_WRITE_BUFFER 02],
							[60 1C],
		/* Frame Compensation 82:off 02:on */
						[MTK_LCM_CMD_TYPE_HEX_WRITE_BUFFER 03],
							[BD 21 82],
						[MTK_LCM_CMD_TYPE_HEX_WRITE_BUFFER 02],
							[F7 0F],
						[MTK_LCM_CMD_TYPE_HEX_WRITE_BUFFER 03],
							[FC A5 A5],
						[MTK_LCM_CMD_TYPE_HEX_WRITE_BUFFER 03],
							[F0 A5 A5],
						[MTK_LCM_TYPE_HEX_END];
				};

				lcm-ops-dsi-fps-switch-before-powerdown {
					compatible =
						"mediatek,lcm-ops-dsi-fps-switch-before-powerdown";

					fps-switch-mode-list;
					default-fps-switch-table;
				};

				/* set min fps cmd for msync 2.0 feature */
				msync-set-min-fps {
					compatible =
						"mediatek,lcm-ops-dsi-msync-set-min-fps";

					//wqhd 120fps
					msync-min-fps-list-0-1440-3216-120 =
						<120 90 72 60 51 45 40 36 33 30 24>;
					msync-set-min-fps-table-0-1440-3216-120 =
						[MTK_LCM_CMD_TYPE_HEX_WRITE_BUFFER 04],
								[b0 00 18 60],
						//120fps
						[MTK_LCM_CMD_TYPE_HEX_WRITE_BUFFER_CONDITION 05],
						[MTK_LCM_INPUT_TYPE_HEX_CURRENT_FPS 78 60 00 00],
						//90fps
						[MTK_LCM_CMD_TYPE_HEX_WRITE_BUFFER_CONDITION 05],
						[MTK_LCM_INPUT_TYPE_HEX_CURRENT_FPS 5a 60 00 01],
						//72fps
						[MTK_LCM_CMD_TYPE_HEX_WRITE_BUFFER_CONDITION 05],
						[MTK_LCM_INPUT_TYPE_HEX_CURRENT_FPS 48 60 00 02],
						//60fps
						[MTK_LCM_CMD_TYPE_HEX_WRITE_BUFFER_CONDITION 05],
						[MTK_LCM_INPUT_TYPE_HEX_CURRENT_FPS 3C 60 00 03],
						//51fps
						[MTK_LCM_CMD_TYPE_HEX_WRITE_BUFFER_CONDITION 05],
						[MTK_LCM_INPUT_TYPE_HEX_CURRENT_FPS 33 60 00 04],
						//45fps
						[MTK_LCM_CMD_TYPE_HEX_WRITE_BUFFER_CONDITION 05],
						[MTK_LCM_INPUT_TYPE_HEX_CURRENT_FPS 2d 60 00 05],
						//40fps
						[MTK_LCM_CMD_TYPE_HEX_WRITE_BUFFER_CONDITION 05],
						[MTK_LCM_INPUT_TYPE_HEX_CURRENT_FPS 28 60 00 06],
						//36fps
						[MTK_LCM_CMD_TYPE_HEX_WRITE_BUFFER_CONDITION 05],
						[MTK_LCM_INPUT_TYPE_HEX_CURRENT_FPS 24 60 00 07],
						//33fps
						[MTK_LCM_CMD_TYPE_HEX_WRITE_BUFFER_CONDITION 05],
						[MTK_LCM_INPUT_TYPE_HEX_CURRENT_FPS 21 60 00 08],
						//30fps
						[MTK_LCM_CMD_TYPE_HEX_WRITE_BUFFER_CONDITION 05],
						[MTK_LCM_INPUT_TYPE_HEX_CURRENT_FPS 1e 60 00 09],
						//24fps
						[MTK_LCM_CMD_TYPE_HEX_WRITE_BUFFER_CONDITION 05],
						[MTK_LCM_INPUT_TYPE_HEX_CURRENT_FPS 18 60 00 0c],
						[MTK_LCM_TYPE_HEX_END];

					//wqhd 90fps
					msync-min-fps-list-1-1440-3216-90 =
						<90 72 60 51 45 40 36 33 30 24>;
					msync-set-min-fps-table-1-1440-3216-90 =
						[MTK_LCM_CMD_TYPE_HEX_WRITE_BUFFER 04],
								[b0 00 18 60],
						//90fps
						[MTK_LCM_CMD_TYPE_HEX_WRITE_BUFFER_CONDITION 05],
						[MTK_LCM_INPUT_TYPE_HEX_CURRENT_FPS 5a 60 04 01],
						//72fps
						[MTK_LCM_CMD_TYPE_HEX_WRITE_BUFFER_CONDITION 05],
						[MTK_LCM_INPUT_TYPE_HEX_CURRENT_FPS 48 60 04 02],
						//60fps
						[MTK_LCM_CMD_TYPE_HEX_WRITE_BUFFER_CONDITION 05],
						[MTK_LCM_INPUT_TYPE_HEX_CURRENT_FPS 3C 60 04 03],
						//51fps
						[MTK_LCM_CMD_TYPE_HEX_WRITE_BUFFER_CONDITION 05],
						[MTK_LCM_INPUT_TYPE_HEX_CURRENT_FPS 33 60 04 04],
						//45fps
						[MTK_LCM_CMD_TYPE_HEX_WRITE_BUFFER_CONDITION 05],
						[MTK_LCM_INPUT_TYPE_HEX_CURRENT_FPS 2d 60 04 05],
						//40fps
						[MTK_LCM_CMD_TYPE_HEX_WRITE_BUFFER_CONDITION 05],
						[MTK_LCM_INPUT_TYPE_HEX_CURRENT_FPS 28 60 04 06],
						//36fps
						[MTK_LCM_CMD_TYPE_HEX_WRITE_BUFFER_CONDITION 05],
						[MTK_LCM_INPUT_TYPE_HEX_CURRENT_FPS 24 60 04 07],
						//33fps
						[MTK_LCM_CMD_TYPE_HEX_WRITE_BUFFER_CONDITION 05],
						[MTK_LCM_INPUT_TYPE_HEX_CURRENT_FPS 21 60 04 08],
						//30fps
						[MTK_LCM_CMD_TYPE_HEX_WRITE_BUFFER_CONDITION 05],
						[MTK_LCM_INPUT_TYPE_HEX_CURRENT_FPS 1e 60 04 09],
						//24fps
						[MTK_LCM_CMD_TYPE_HEX_WRITE_BUFFER_CONDITION 05],
						[MTK_LCM_INPUT_TYPE_HEX_CURRENT_FPS 18 60 04 0c],
						[MTK_LCM_TYPE_HEX_END];

					//wqhd 72fps
					msync-min-fps-list-2-1440-3216-72 =
						<72 60 51 45 40 36 33 30 28 26 24>;
					msync-set-min-fps-table-2-1440-3216-72 =
						[MTK_LCM_CMD_TYPE_HEX_WRITE_BUFFER 04],
								[b0 00 18 60],
						//72fps
						[MTK_LCM_CMD_TYPE_HEX_WRITE_BUFFER_CONDITION 05],
						[MTK_LCM_INPUT_TYPE_HEX_CURRENT_FPS 48 60 08 03],
						//60fps
						[MTK_LCM_CMD_TYPE_HEX_WRITE_BUFFER_CONDITION 05],
						[MTK_LCM_INPUT_TYPE_HEX_CURRENT_FPS 3C 60 08 03],
						//51fps
						[MTK_LCM_CMD_TYPE_HEX_WRITE_BUFFER_CONDITION 05],
						[MTK_LCM_INPUT_TYPE_HEX_CURRENT_FPS 33 60 08 04],
						//45fps
						[MTK_LCM_CMD_TYPE_HEX_WRITE_BUFFER_CONDITION 05],
						[MTK_LCM_INPUT_TYPE_HEX_CURRENT_FPS 2d 60 08 05],
						//40fps
						[MTK_LCM_CMD_TYPE_HEX_WRITE_BUFFER_CONDITION 05],
						[MTK_LCM_INPUT_TYPE_HEX_CURRENT_FPS 28 60 08 06],
						//36fps
						[MTK_LCM_CMD_TYPE_HEX_WRITE_BUFFER_CONDITION 05],
						[MTK_LCM_INPUT_TYPE_HEX_CURRENT_FPS 24 60 08 07],
						//33fps
						[MTK_LCM_CMD_TYPE_HEX_WRITE_BUFFER_CONDITION 05],
						[MTK_LCM_INPUT_TYPE_HEX_CURRENT_FPS 21 60 08 08],
						//30fps
						[MTK_LCM_CMD_TYPE_HEX_WRITE_BUFFER_CONDITION 05],
						[MTK_LCM_INPUT_TYPE_HEX_CURRENT_FPS 1e 60 08 09],
						//28fps
						[MTK_LCM_CMD_TYPE_HEX_WRITE_BUFFER_CONDITION 05],
						[MTK_LCM_INPUT_TYPE_HEX_CURRENT_FPS 1c 60 08 0a],
						//26fps
						[MTK_LCM_CMD_TYPE_HEX_WRITE_BUFFER_CONDITION 05],
						[MTK_LCM_INPUT_TYPE_HEX_CURRENT_FPS 1a 60 08 0b],
						//24fps
						[MTK_LCM_CMD_TYPE_HEX_WRITE_BUFFER_CONDITION 05],
						[MTK_LCM_INPUT_TYPE_HEX_CURRENT_FPS 18 60 08 0c],
						[MTK_LCM_TYPE_HEX_END];

					//wqhd 60fps
					msync-min-fps-list-3-1440-3216-60 =
						<60 51 45 40 36 33 30 28 26 24>;
					msync-set-min-fps-table-3-1440-3216-60 =
						[MTK_LCM_CMD_TYPE_HEX_WRITE_BUFFER 04],
								[b0 00 18 60],
						//60fps
						[MTK_LCM_CMD_TYPE_HEX_WRITE_BUFFER_CONDITION 05],
						[MTK_LCM_INPUT_TYPE_HEX_CURRENT_FPS 3C 60 0c 03],
						//51fps
						[MTK_LCM_CMD_TYPE_HEX_WRITE_BUFFER_CONDITION 05],
						[MTK_LCM_INPUT_TYPE_HEX_CURRENT_FPS 33 60 0c 04],
						//45fps
						[MTK_LCM_CMD_TYPE_HEX_WRITE_BUFFER_CONDITION 05],
						[MTK_LCM_INPUT_TYPE_HEX_CURRENT_FPS 2d 60 0c 05],
						//40fps
						[MTK_LCM_CMD_TYPE_HEX_WRITE_BUFFER_CONDITION 05],
						[MTK_LCM_INPUT_TYPE_HEX_CURRENT_FPS 28 60 0c 06],
						//36fps
						[MTK_LCM_CMD_TYPE_HEX_WRITE_BUFFER_CONDITION 05],
						[MTK_LCM_INPUT_TYPE_HEX_CURRENT_FPS 24 60 0c 07],
						//33fps
						[MTK_LCM_CMD_TYPE_HEX_WRITE_BUFFER_CONDITION 05],
						[MTK_LCM_INPUT_TYPE_HEX_CURRENT_FPS 21 60 0c 08],
						//30fps
						[MTK_LCM_CMD_TYPE_HEX_WRITE_BUFFER_CONDITION 05],
						[MTK_LCM_INPUT_TYPE_HEX_CURRENT_FPS 1e 60 0c 09],
						//28fps
						[MTK_LCM_CMD_TYPE_HEX_WRITE_BUFFER_CONDITION 05],
						[MTK_LCM_INPUT_TYPE_HEX_CURRENT_FPS 1c 60 0c 0a],
						//26fps
						[MTK_LCM_CMD_TYPE_HEX_WRITE_BUFFER_CONDITION 05],
						[MTK_LCM_INPUT_TYPE_HEX_CURRENT_FPS 1a 60 0c 0b],
						//24fps
						[MTK_LCM_CMD_TYPE_HEX_WRITE_BUFFER_CONDITION 05],
						[MTK_LCM_INPUT_TYPE_HEX_CURRENT_FPS 18 60 0c 0c],
						//21fps
						[MTK_LCM_CMD_TYPE_HEX_WRITE_BUFFER_CONDITION 05],
						[MTK_LCM_INPUT_TYPE_HEX_CURRENT_FPS 15 60 0c 0d],
						[MTK_LCM_TYPE_HEX_END];
				};
			};
		};
	};
};

